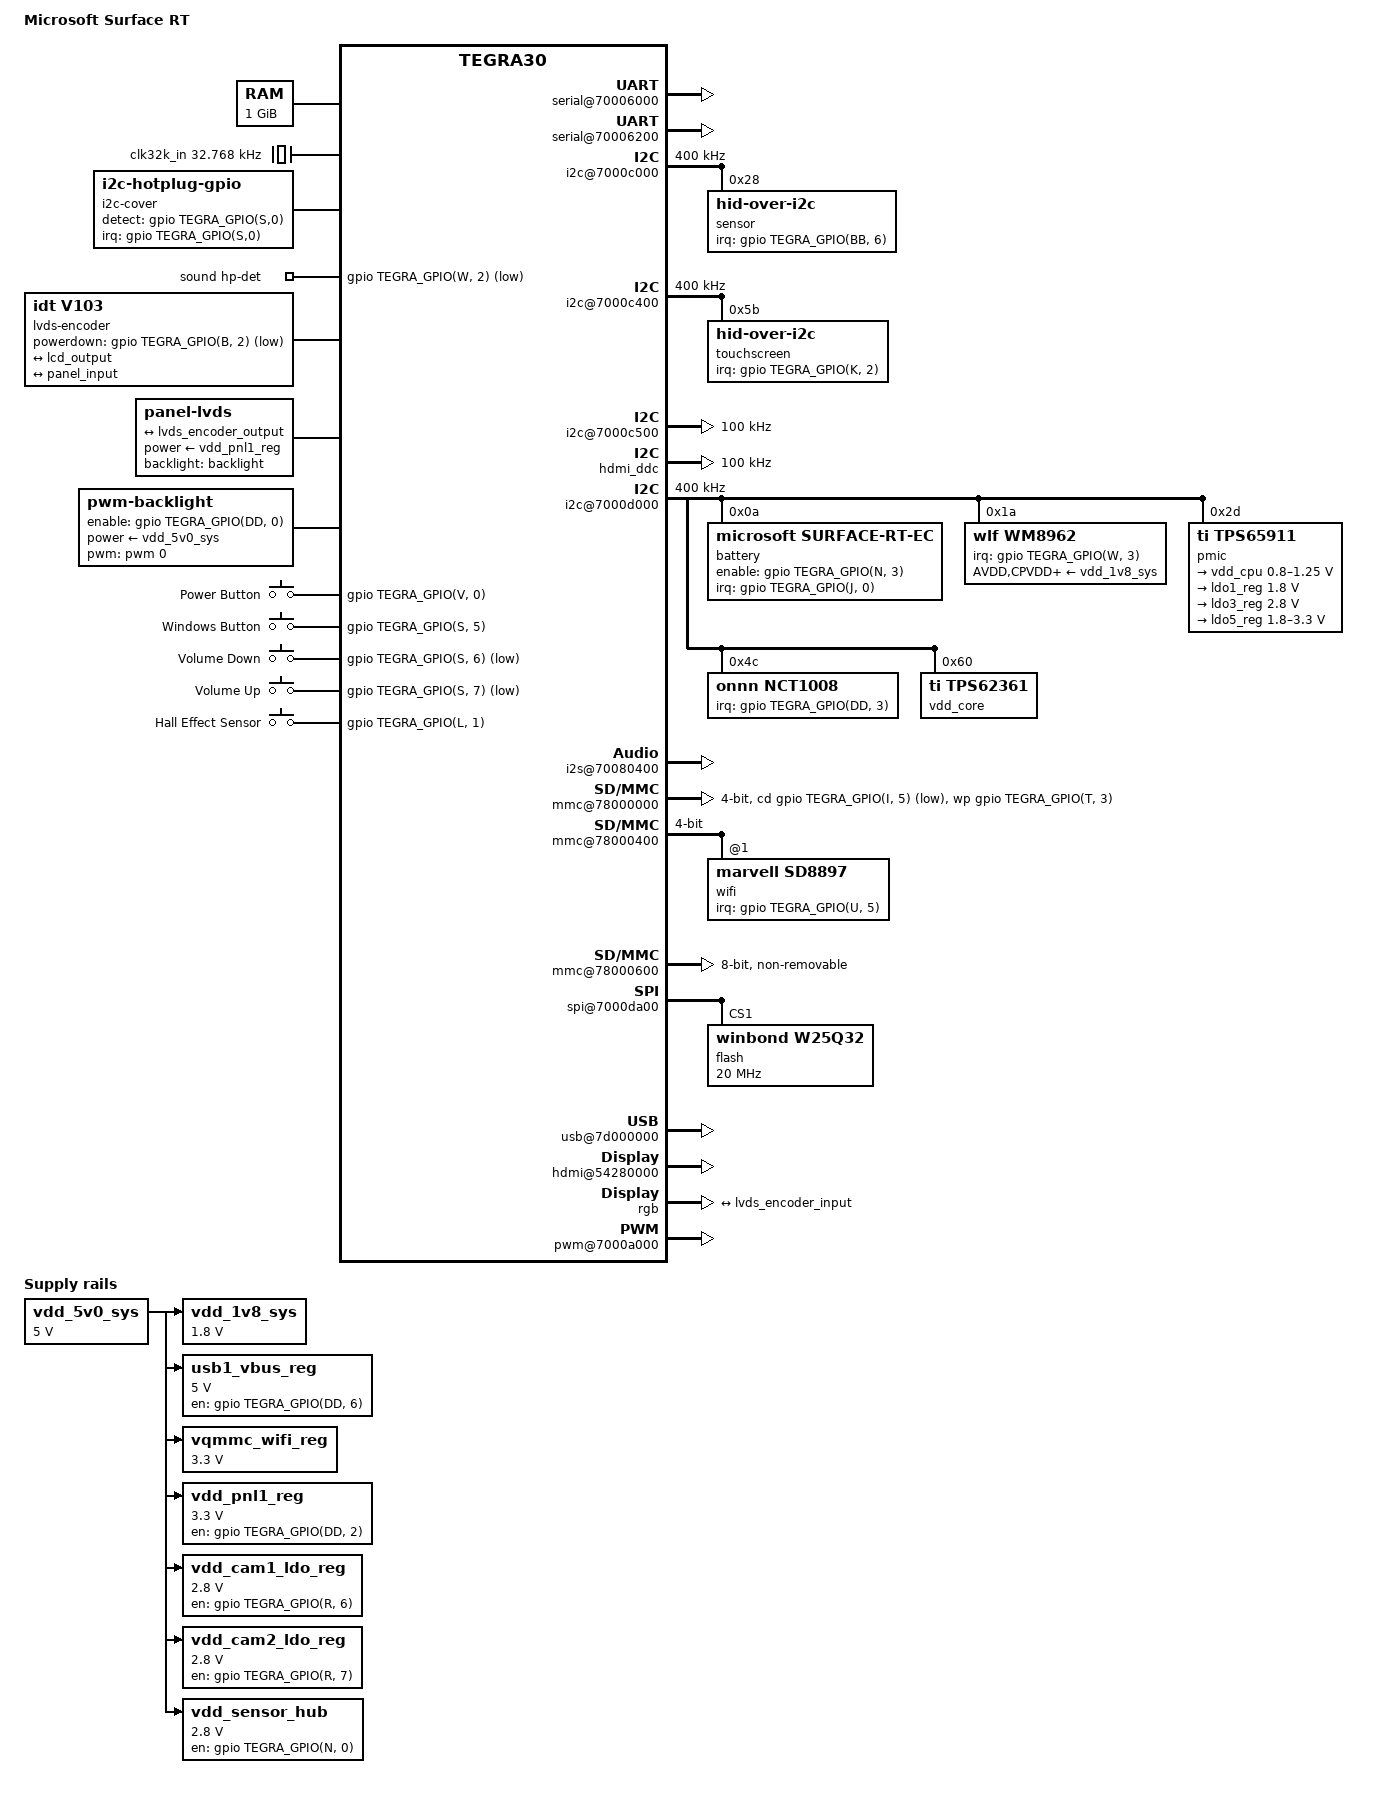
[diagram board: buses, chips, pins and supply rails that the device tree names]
// SPDX-License-Identifier: GPL-2.0

/dts-v1/;

#include "tegra30.dtsi"
#include "tegra30-cpu-opp.dtsi"
#include "tegra30-cpu-opp-microvolt.dtsi"
#include <dt-bindings/input/input.h>

/ {
	model = "Microsoft Surface RT";
	compatible = "microsoft,surface-rt", "nvidia,tegra30";

	aliases {
		mmc0 = &sdmmc4; /* eMMC */
		mmc1 = &sdmmc1; /* uSD slot */
		mmc2 = &sdmmc3; /* WiFi */
		rtc0 = &pmic;
		rtc1 = "/rtc@7000e000";
		serial0 = &uarta; /* console */
		serial1 = &uartc; /* Bluetooth */
	};

	chosen {
		stdout-path = "serial0:115200n8";
	};

	/* 2GB DDR3 Memory */
	memory@80000000 {
		reg = <0x80000000 0x40000000>; // 1 GiB is wrong size but 2GB doesn't work atm
	};

	/* clock from PMIC */
	clk32k_in: clock-32 {
		compatible = "fixed-clock";
		clock-frequency = <32768>;
		#clock-cells = <0>;
	};

	pinmux@70000868 {
		pinctrl-names = "default";
		pinctrl-0 = <&state_default>;

		state_default: pinmux {
			/* HDMI HOTPLUG_DETECT */
			hdmi-interrupt {
				nvidia,pins = "hdmi_int_pn7";
				nvidia,function = "hdmi";
				nvidia,pull = <TEGRA_PIN_PULL_NONE>;
				nvidia,tristate = <TEGRA_PIN_ENABLE>;
				nvidia,enable-input = <TEGRA_PIN_ENABLE>;
			};

			vol-keys {
				nvidia,pins = "kb_row14_ps6", //down
					      "kb_row15_ps7"; //up
				nvidia,pull = <TEGRA_PIN_PULL_NONE>;
				nvidia,tristate = <TEGRA_PIN_ENABLE>;
				nvidia,enable-input = <TEGRA_PIN_ENABLE>;
			};

			backlight-pwm {
				nvidia,pins = "gmi_ad8_ph0";
				nvidia,function = "pwm0";
				nvidia,pull = <TEGRA_PIN_PULL_NONE>;
				nvidia,tristate = <TEGRA_PIN_DISABLE>;
				nvidia,enable-input = <TEGRA_PIN_DISABLE>;
			};

			wifi-interrupt {
				nvidia,pins = "pu5";
				nvidia,pull = <TEGRA_PIN_PULL_DOWN>;
				nvidia,tristate = <TEGRA_PIN_DISABLE>;
				nvidia,enable-input = <TEGRA_PIN_ENABLE>;
			};

			sdmmc1-wp {
				nvidia,pins = "vi_d11_pt3";
				nvidia,pull = <TEGRA_PIN_PULL_NONE>;
				nvidia,tristate = <TEGRA_PIN_DISABLE>;
				nvidia,enable-input = <TEGRA_PIN_ENABLE>;
			};

			charger-interrupt {
				nvidia,pins = "gmi_cs0_n_pj0";
				nvidia,pull = <TEGRA_PIN_PULL_NONE>;
				nvidia,tristate = <TEGRA_PIN_ENABLE>;
				nvidia,enable-input = <TEGRA_PIN_ENABLE>;
			};
		};
	};

	serial@70006000 {
		status = "okay";
	};

	serial@70006200 {
		status = "okay";
		compatible = "nvidia,tegra30-hsuart";

		/* Bluetooth - Marvell 88W8797*/
	};

	/* MS HID - I2C1 */
	i2c@7000c000 {
		status = "okay";
		clock-frequency = <400000>;

		/* Sensor Collection at 0x28 */
		sensor@28 {
			compatible = "hid-over-i2c";
			reg = <0x28>;
			hid-descr-addr = <0x0001>;
			interrupt-parent = <&gpio>;
			interrupts = <TEGRA_GPIO(BB, 6) IRQ_TYPE_LEVEL_LOW>;
		};
		/* EDID at 0x50*/
	};

	i2c-cover {
		compatible = "i2c-hotplug-gpio";

		#address-cells = <1>;
		#size-cells = <0>;

		interrupts-extended = <&gpio TEGRA_GPIO(S,0) IRQ_TYPE_EDGE_BOTH>;
		detect-gpios = <&gpio TEGRA_GPIO(S,0) GPIO_ACTIVE_HIGH>;

		i2c-parent = <&i2c1>;

		cover@0 {
			compatible = "hid-over-i2c";
			reg = <0x00>;
			hid-descr-addr = <0x0041>;
			interrupt-parent = <&gpio>;
			interrupts = <TEGRA_GPIO(O, 5) IRQ_TYPE_LEVEL_LOW>;
		};
	};

	/* Daughter board - I2C2 */
	i2c@7000c400 {
		status = "okay";
		clock-frequency = <400000>;

		/* Atmel Maxtouch, HID over I2C */
		touchscreen@5b {
			compatible = "hid-over-i2c";
			reg = <0x5b>;
			hid-descr-addr = <0x0000>;
			interrupt-parent = <&gpio>;
			interrupts = <TEGRA_GPIO(K, 2) IRQ_TYPE_LEVEL_LOW>;
		};
	};

	/* Cams - I2C3 */
	i2c@7000c500 {
		status = "okay";
		clock-frequency = <100000>;
		/* Cams at 0x10 and 0x72 */
	};

	/* HDMI DisplayDataChannel - I2C4 */
	hdmi_ddc: i2c@7000c700 {
		status = "okay";
		clock-frequency = <100000>;
	};

	/* System bus - I2C5 */
	i2c@7000d000 {
		status = "okay";
		clock-frequency = <400000>;

		battery@a {
			compatible = "microsoft,surface-rt-ec";
			reg = <0x0a>;
			enable-gpios = <&gpio TEGRA_GPIO(N, 3) GPIO_ACTIVE_HIGH>;
			interrupt-parent = <&gpio>;
			interrupts = <TEGRA_GPIO(J, 0) IRQ_TYPE_EDGE_RISING>;
		};

		wm8962: audio-codec@1a {
			compatible = "wlf,wm8962";
			reg = <0x1a>;
			interrupt-parent = <&gpio>;
			interrupts = <TEGRA_GPIO(W, 3) IRQ_TYPE_LEVEL_HIGH>;

			AVDD-supply  = <&vdd_1v8_sys>;
			CPVDD-supply = <&vdd_1v8_sys>;
			DBVDD-supply = <&vdd_1v8_sys>;
			DCVDD-supply = <&vdd_1v8_sys>;
			MICVDD-supply = <&vdd_1v8_sys>;
			PLLVDD-supply = <&vdd_1v8_sys>;
			SPKVDD1-supply = <&vdd_1v8_sys>;
			SPKVDD2-supply = <&vdd_1v8_sys>;
		};

		pmic: pmic@2d {
			compatible = "ti,tps65911";
			reg = <0x2d>;

			interrupts = <GIC_SPI 86 IRQ_TYPE_LEVEL_HIGH>;
			#interrupt-cells = <2>;
			interrupt-controller;

			ti,system-power-controller;

			#gpio-cells = <2>;
			gpio-controller;

			regulators {
				vdd_cpu: vddctrl {
					regulator-name = "vdd_cpu,vdd_sys";
					regulator-min-microvolt = <800000>;
					regulator-max-microvolt = <1250000>;
					regulator-coupled-with = <&vdd_core>;
					regulator-coupled-max-spread = <300000>;
					regulator-max-step-microvolt = <100000>;
					regulator-always-on;
					ti,regulator-ext-sleep-control = <1>;

					nvidia,tegra-cpu-regulator;
				};

				ldo1_reg: ldo1 {
					regulator-name = "tCoverAndSensorCollection";
					regulator-min-microvolt = <1800000>;
					regulator-max-microvolt = <1800000>;
					regulator-always-on;
					regulator-boot-on;
				};

				ldo3_reg: ldo3 {
					regulator-name = "tCoverPower";
					regulator-min-microvolt = <2800000>;
					regulator-max-microvolt = <2800000>;
					regulator-always-on;
					regulator-boot-on;
				};

				ldo5_reg: ldo5 {
					regulator-name = "vddio_sdmmc";
					regulator-min-microvolt = <1800000>;
					regulator-max-microvolt = <3300000>;
					regulator-always-on;
				};
			};
		};

		nct1008: temperature-sensor@4c {
			compatible = "onnn,nct1008";
			reg = <0x4c>;
			interrupt-parent = <&gpio>;
			interrupts = <TEGRA_GPIO(DD, 3) IRQ_TYPE_EDGE_FALLING>;
			#thermal-sensor-cells = <1>;
		};

		vdd_core: core-regulator@60 {
			compatible = "ti,tps62361";
			reg = <0x60>;

			regulator-name = "tps62361-vout";
			regulator-min-microvolt = <500000>;
			regulator-max-microvolt = <1350000>;
			regulator-coupled-with = <&vdd_cpu>;
			regulator-coupled-max-spread = <300000>;
			regulator-max-step-microvolt = <100000>;
			regulator-boot-on;
			regulator-always-on;
			ti,enable-vout-discharge;
			ti,vsel0-state-high;
			ti,vsel1-state-high;

			nvidia,tegra-core-regulator;
		};
	};

	pmc@7000e400 {
		status = "okay";
		nvidia,invert-interrupt;
		nvidia,suspend-mode = <2>;
		nvidia,cpu-pwr-good-time = <2000>;
		nvidia,cpu-pwr-off-time = <200>;
		nvidia,core-pwr-good-time = <3845 3845>;
		nvidia,core-pwr-off-time = <0>;
		nvidia,core-power-req-active-high;
		nvidia,sys-clock-req-active-high;

		core-supply = <&vdd_core>;

		i2c-thermtrip {
			nvidia,i2c-controller-id = <4>;
			nvidia,bus-addr = <0x2d>;
			nvidia,reg-addr = <0x3f>;
			nvidia,reg-data = <0x80>;
		};
	};

	memory-controller@7000f000 {
		emc-timings-0 {
			nvidia,ram-code = <0>;
			timing-51000000 {
				clock-frequency = <51000000>;
				nvidia,emem-configuration = <
					0x00010003 /* MC_EMEM_ARB_CFG */
					0xc0000010 /* MC_EMEM_ARB_OUTSTANDING_REQ */
					0x00000001 /* MC_EMEM_ARB_TIMING_RCD */
					0x00000001 /* MC_EMEM_ARB_TIMING_RP */
					0x00000002 /* MC_EMEM_ARB_TIMING_RC */
					0x00000000 /* MC_EMEM_ARB_TIMING_RAS */
					0x00000001 /* MC_EMEM_ARB_TIMING_FAW */
					0x00000001 /* MC_EMEM_ARB_TIMING_RRD */
					0x00000003 /* MC_EMEM_ARB_TIMING_RAP2PRE */
					0x00000008 /* MC_EMEM_ARB_TIMING_WAP2PRE */
					0x00000002 /* MC_EMEM_ARB_TIMING_R2R */
					0x00000001 /* MC_EMEM_ARB_TIMING_W2W */
					0x00000002 /* MC_EMEM_ARB_TIMING_R2W */
					0x00000006 /* MC_EMEM_ARB_TIMING_W2R */
					0x06020102 /* MC_EMEM_ARB_DA_TURNS */
					0x000a0502 /* MC_EMEM_ARB_DA_COVERS */
					0x74630303 /* MC_EMEM_ARB_MISC0 */
					0x001f0000 /* MC_EMEM_ARB_RING1_THROTTLE */
				>;
			};
			timing-102000000 {
				clock-frequency = <102000000>;
				nvidia,emem-configuration = <
					0x00000003 /* MC_EMEM_ARB_CFG */
					0xc0000018 /* MC_EMEM_ARB_OUTSTANDING_REQ */
					0x00000001 /* MC_EMEM_ARB_TIMING_RCD */
					0x00000001 /* MC_EMEM_ARB_TIMING_RP */
					0x00000003 /* MC_EMEM_ARB_TIMING_RC */
					0x00000000 /* MC_EMEM_ARB_TIMING_RAS */
					0x00000001 /* MC_EMEM_ARB_TIMING_FAW */
					0x00000001 /* MC_EMEM_ARB_TIMING_RRD */
					0x00000003 /* MC_EMEM_ARB_TIMING_RAP2PRE */
					0x00000008 /* MC_EMEM_ARB_TIMING_WAP2PRE */
					0x00000002 /* MC_EMEM_ARB_TIMING_R2R */
					0x00000001 /* MC_EMEM_ARB_TIMING_W2W */
					0x00000002 /* MC_EMEM_ARB_TIMING_R2W */
					0x00000006 /* MC_EMEM_ARB_TIMING_W2R */
					0x06020102 /* MC_EMEM_ARB_DA_TURNS */
					0x000a0503 /* MC_EMEM_ARB_DA_COVERS */
					0x73c30504 /* MC_EMEM_ARB_MISC0 */
					0x001f0000 /* MC_EMEM_ARB_RING1_THROTTLE */
				>;
			};
			timing-204000000 {
				clock-frequency = <204000000>;
				nvidia,emem-configuration = <
					0x00000006 /* MC_EMEM_ARB_CFG */
					0xc0000025 /* MC_EMEM_ARB_OUTSTANDING_REQ */
					0x00000001 /* MC_EMEM_ARB_TIMING_RCD */
					0x00000001 /* MC_EMEM_ARB_TIMING_RP */
					0x00000005 /* MC_EMEM_ARB_TIMING_RC */
					0x00000002 /* MC_EMEM_ARB_TIMING_RAS */
					0x00000003 /* MC_EMEM_ARB_TIMING_FAW */
					0x00000001 /* MC_EMEM_ARB_TIMING_RRD */
					0x00000003 /* MC_EMEM_ARB_TIMING_RAP2PRE */
					0x00000008 /* MC_EMEM_ARB_TIMING_WAP2PRE */
					0x00000002 /* MC_EMEM_ARB_TIMING_R2R */
					0x00000001 /* MC_EMEM_ARB_TIMING_W2W */
					0x00000002 /* MC_EMEM_ARB_TIMING_R2W */
					0x00000006 /* MC_EMEM_ARB_TIMING_W2R */
					0x06020102 /* MC_EMEM_ARB_DA_TURNS */
					0x000a0505 /* MC_EMEM_ARB_DA_COVERS */
					0x73840a06 /* MC_EMEM_ARB_MISC0 */
					0x001f0000 /* MC_EMEM_ARB_RING1_THROTTLE */
				>;
			};
			timing-375000000 {
				clock-frequency = <375000000>;
				nvidia,emem-configuration = <
					0x0000000b /* MC_EMEM_ARB_CFG */
					0xc0000044 /* MC_EMEM_ARB_OUTSTANDING_REQ */
					0x00000001 /* MC_EMEM_ARB_TIMING_RCD */
					0x00000002 /* MC_EMEM_ARB_TIMING_RP */
					0x00000009 /* MC_EMEM_ARB_TIMING_RC */
					0x00000005 /* MC_EMEM_ARB_TIMING_RAS */
					0x00000005 /* MC_EMEM_ARB_TIMING_FAW */
					0x00000001 /* MC_EMEM_ARB_TIMING_RRD */
					0x00000002 /* MC_EMEM_ARB_TIMING_RAP2PRE */
					0x00000008 /* MC_EMEM_ARB_TIMING_WAP2PRE */
					0x00000002 /* MC_EMEM_ARB_TIMING_R2R */
					0x00000002 /* MC_EMEM_ARB_TIMING_W2W */
					0x00000003 /* MC_EMEM_ARB_TIMING_R2W */
					0x00000006 /* MC_EMEM_ARB_TIMING_W2R */
					0x06030202 /* MC_EMEM_ARB_DA_TURNS */
					0x000d0709 /* MC_EMEM_ARB_DA_COVERS */
					0x7086110a /* MC_EMEM_ARB_MISC0 */
					0x001f0000 /* MC_EMEM_ARB_RING1_THROTTLE */
				>;
			};
			timing-750000000 {
				clock-frequency = <750000000>;
				nvidia,emem-configuration = <
					0x00000016 /* MC_EMEM_ARB_CFG */
					0xc0000087 /* MC_EMEM_ARB_OUTSTANDING_REQ */
					0x00000004 /* MC_EMEM_ARB_TIMING_RCD */
					0x00000005 /* MC_EMEM_ARB_TIMING_RP */
					0x00000012 /* MC_EMEM_ARB_TIMING_RC */
					0x0000000c /* MC_EMEM_ARB_TIMING_RAS */
					0x0000000b /* MC_EMEM_ARB_TIMING_FAW */
					0x00000002 /* MC_EMEM_ARB_TIMING_RRD */
					0x00000003 /* MC_EMEM_ARB_TIMING_RAP2PRE */
					0x0000000c /* MC_EMEM_ARB_TIMING_WAP2PRE */
					0x00000002 /* MC_EMEM_ARB_TIMING_R2R */
					0x00000002 /* MC_EMEM_ARB_TIMING_W2W */
					0x00000004 /* MC_EMEM_ARB_TIMING_R2W */
					0x00000008 /* MC_EMEM_ARB_TIMING_W2R */
					0x08040202 /* MC_EMEM_ARB_DA_TURNS */
					0x00160d12 /* MC_EMEM_ARB_DA_COVERS */
					0x710c2213 /* MC_EMEM_ARB_MISC0 */
					0x001f0000 /* MC_EMEM_ARB_RING1_THROTTLE */
				>;
			};
		};
		emc-timings-1 {
			nvidia,ram-code = <1>;
			timing-51000000 {
				clock-frequency = <51000000>;
				nvidia,emem-configuration = <
					0x00010003 /* MC_EMEM_ARB_CFG */
					0xc0000010 /* MC_EMEM_ARB_OUTSTANDING_REQ */
					0x00000001 /* MC_EMEM_ARB_TIMING_RCD */
					0x00000001 /* MC_EMEM_ARB_TIMING_RP */
					0x00000002 /* MC_EMEM_ARB_TIMING_RC */
					0x00000000 /* MC_EMEM_ARB_TIMING_RAS */
					0x00000001 /* MC_EMEM_ARB_TIMING_FAW */
					0x00000001 /* MC_EMEM_ARB_TIMING_RRD */
					0x00000003 /* MC_EMEM_ARB_TIMING_RAP2PRE */
					0x00000008 /* MC_EMEM_ARB_TIMING_WAP2PRE */
					0x00000002 /* MC_EMEM_ARB_TIMING_R2R */
					0x00000001 /* MC_EMEM_ARB_TIMING_W2W */
					0x00000002 /* MC_EMEM_ARB_TIMING_R2W */
					0x00000006 /* MC_EMEM_ARB_TIMING_W2R */
					0x06020102 /* MC_EMEM_ARB_DA_TURNS */
					0x000a0502 /* MC_EMEM_ARB_DA_COVERS */
					0x74630303 /* MC_EMEM_ARB_MISC0 */
					0x001f0000 /* MC_EMEM_ARB_RING1_THROTTLE */
				>;
			};
			timing-102000000 {
				clock-frequency = <102000000>;
				nvidia,emem-configuration = <
					0x00000003 /* MC_EMEM_ARB_CFG */
					0xc0000018 /* MC_EMEM_ARB_OUTSTANDING_REQ */
					0x00000001 /* MC_EMEM_ARB_TIMING_RCD */
					0x00000001 /* MC_EMEM_ARB_TIMING_RP */
					0x00000003 /* MC_EMEM_ARB_TIMING_RC */
					0x00000000 /* MC_EMEM_ARB_TIMING_RAS */
					0x00000001 /* MC_EMEM_ARB_TIMING_FAW */
					0x00000001 /* MC_EMEM_ARB_TIMING_RRD */
					0x00000003 /* MC_EMEM_ARB_TIMING_RAP2PRE */
					0x00000008 /* MC_EMEM_ARB_TIMING_WAP2PRE */
					0x00000002 /* MC_EMEM_ARB_TIMING_R2R */
					0x00000001 /* MC_EMEM_ARB_TIMING_W2W */
					0x00000002 /* MC_EMEM_ARB_TIMING_R2W */
					0x00000006 /* MC_EMEM_ARB_TIMING_W2R */
					0x06020102 /* MC_EMEM_ARB_DA_TURNS */
					0x000a0503 /* MC_EMEM_ARB_DA_COVERS */
					0x73c30504 /* MC_EMEM_ARB_MISC0 */
					0x001f0000 /* MC_EMEM_ARB_RING1_THROTTLE */
				>;
			};
			timing-204000000 {
				clock-frequency = <204000000>;
				nvidia,emem-configuration = <
					0x00000006 /* MC_EMEM_ARB_CFG */
					0xc0000025 /* MC_EMEM_ARB_OUTSTANDING_REQ */
					0x00000001 /* MC_EMEM_ARB_TIMING_RCD */
					0x00000001 /* MC_EMEM_ARB_TIMING_RP */
					0x00000005 /* MC_EMEM_ARB_TIMING_RC */
					0x00000002 /* MC_EMEM_ARB_TIMING_RAS */
					0x00000003 /* MC_EMEM_ARB_TIMING_FAW */
					0x00000001 /* MC_EMEM_ARB_TIMING_RRD */
					0x00000003 /* MC_EMEM_ARB_TIMING_RAP2PRE */
					0x00000008 /* MC_EMEM_ARB_TIMING_WAP2PRE */
					0x00000002 /* MC_EMEM_ARB_TIMING_R2R */
					0x00000001 /* MC_EMEM_ARB_TIMING_W2W */
					0x00000002 /* MC_EMEM_ARB_TIMING_R2W */
					0x00000006 /* MC_EMEM_ARB_TIMING_W2R */
					0x06020102 /* MC_EMEM_ARB_DA_TURNS */
					0x000a0505 /* MC_EMEM_ARB_DA_COVERS */
					0x73840a06 /* MC_EMEM_ARB_MISC0 */
					0x001f0000 /* MC_EMEM_ARB_RING1_THROTTLE */
				>;
			};
			timing-375000000 {
				clock-frequency = <375000000>;
				nvidia,emem-configuration = <
					0x0000000b /* MC_EMEM_ARB_CFG */
					0xc0000044 /* MC_EMEM_ARB_OUTSTANDING_REQ */
					0x00000001 /* MC_EMEM_ARB_TIMING_RCD */
					0x00000002 /* MC_EMEM_ARB_TIMING_RP */
					0x00000009 /* MC_EMEM_ARB_TIMING_RC */
					0x00000005 /* MC_EMEM_ARB_TIMING_RAS */
					0x00000005 /* MC_EMEM_ARB_TIMING_FAW */
					0x00000001 /* MC_EMEM_ARB_TIMING_RRD */
					0x00000002 /* MC_EMEM_ARB_TIMING_RAP2PRE */
					0x00000008 /* MC_EMEM_ARB_TIMING_WAP2PRE */
					0x00000002 /* MC_EMEM_ARB_TIMING_R2R */
					0x00000002 /* MC_EMEM_ARB_TIMING_W2W */
					0x00000003 /* MC_EMEM_ARB_TIMING_R2W */
					0x00000006 /* MC_EMEM_ARB_TIMING_W2R */
					0x06030202 /* MC_EMEM_ARB_DA_TURNS */
					0x000d0709 /* MC_EMEM_ARB_DA_COVERS */
					0x7086110a /* MC_EMEM_ARB_MISC0 */
					0x001f0000 /* MC_EMEM_ARB_RING1_THROTTLE */
				>;
			};
			timing-750000000 {
				clock-frequency = <750000000>;
				nvidia,emem-configuration = <
					0x00000016 /* MC_EMEM_ARB_CFG */
					0xc0000087 /* MC_EMEM_ARB_OUTSTANDING_REQ */
					0x00000004 /* MC_EMEM_ARB_TIMING_RCD */
					0x00000005 /* MC_EMEM_ARB_TIMING_RP */
					0x00000012 /* MC_EMEM_ARB_TIMING_RC */
					0x0000000c /* MC_EMEM_ARB_TIMING_RAS */
					0x0000000b /* MC_EMEM_ARB_TIMING_FAW */
					0x00000002 /* MC_EMEM_ARB_TIMING_RRD */
					0x00000003 /* MC_EMEM_ARB_TIMING_RAP2PRE */
					0x0000000c /* MC_EMEM_ARB_TIMING_WAP2PRE */
					0x00000002 /* MC_EMEM_ARB_TIMING_R2R */
					0x00000002 /* MC_EMEM_ARB_TIMING_W2W */
					0x00000004 /* MC_EMEM_ARB_TIMING_R2W */
					0x00000008 /* MC_EMEM_ARB_TIMING_W2R */
					0x08040202 /* MC_EMEM_ARB_DA_TURNS */
					0x00160d12 /* MC_EMEM_ARB_DA_COVERS */
					0x710c2213 /* MC_EMEM_ARB_MISC0 */
					0x001f0000 /* MC_EMEM_ARB_RING1_THROTTLE */
				>;
			};
		};
		emc-timings-2 {
			nvidia,ram-code = <2>;
			timing-51000000 {
				clock-frequency = <51000000>;
				nvidia,emem-configuration = <
					0x00010001 /* MC_EMEM_ARB_CFG */
					0xc0000010 /* MC_EMEM_ARB_OUTSTANDING_REQ */
					0x00000001 /* MC_EMEM_ARB_TIMING_RCD */
					0x00000001 /* MC_EMEM_ARB_TIMING_RP */
					0x00000002 /* MC_EMEM_ARB_TIMING_RC */
					0x00000000 /* MC_EMEM_ARB_TIMING_RAS */
					0x00000001 /* MC_EMEM_ARB_TIMING_FAW */
					0x00000001 /* MC_EMEM_ARB_TIMING_RRD */
					0x00000002 /* MC_EMEM_ARB_TIMING_RAP2PRE */
					0x00000008 /* MC_EMEM_ARB_TIMING_WAP2PRE */
					0x00000002 /* MC_EMEM_ARB_TIMING_R2R */
					0x00000001 /* MC_EMEM_ARB_TIMING_W2W */
					0x00000002 /* MC_EMEM_ARB_TIMING_R2W */
					0x00000006 /* MC_EMEM_ARB_TIMING_W2R */
					0x06020102 /* MC_EMEM_ARB_DA_TURNS */
					0x000a0402 /* MC_EMEM_ARB_DA_COVERS */
					0x74e30303 /* MC_EMEM_ARB_MISC0 */
					0x001f0000 /* MC_EMEM_ARB_RING1_THROTTLE */
				>;
			};
			timing-102000000 {
				clock-frequency = <102000000>;
				nvidia,emem-configuration = <
					0x00000001 /* MC_EMEM_ARB_CFG */
					0xc0000018 /* MC_EMEM_ARB_OUTSTANDING_REQ */
					0x00000001 /* MC_EMEM_ARB_TIMING_RCD */
					0x00000001 /* MC_EMEM_ARB_TIMING_RP */
					0x00000003 /* MC_EMEM_ARB_TIMING_RC */
					0x00000000 /* MC_EMEM_ARB_TIMING_RAS */
					0x00000001 /* MC_EMEM_ARB_TIMING_FAW */
					0x00000001 /* MC_EMEM_ARB_TIMING_RRD */
					0x00000002 /* MC_EMEM_ARB_TIMING_RAP2PRE */
					0x00000008 /* MC_EMEM_ARB_TIMING_WAP2PRE */
					0x00000002 /* MC_EMEM_ARB_TIMING_R2R */
					0x00000001 /* MC_EMEM_ARB_TIMING_W2W */
					0x00000002 /* MC_EMEM_ARB_TIMING_R2W */
					0x00000006 /* MC_EMEM_ARB_TIMING_W2R */
					0x06020102 /* MC_EMEM_ARB_DA_TURNS */
					0x000a0403 /* MC_EMEM_ARB_DA_COVERS */
					0x74430504 /* MC_EMEM_ARB_MISC0 */
					0x001f0000 /* MC_EMEM_ARB_RING1_THROTTLE */
				>;
			};
			timing-375000000 {
				clock-frequency = <375000000>;
				nvidia,emem-configuration = <
					0x00000005 /* MC_EMEM_ARB_CFG */
					0xc0000044 /* MC_EMEM_ARB_OUTSTANDING_REQ */
					0x00000001 /* MC_EMEM_ARB_TIMING_RCD */
					0x00000002 /* MC_EMEM_ARB_TIMING_RP */
					0x00000009 /* MC_EMEM_ARB_TIMING_RC */
					0x00000005 /* MC_EMEM_ARB_TIMING_RAS */
					0x00000005 /* MC_EMEM_ARB_TIMING_FAW */
					0x00000001 /* MC_EMEM_ARB_TIMING_RRD */
					0x00000002 /* MC_EMEM_ARB_TIMING_RAP2PRE */
					0x00000008 /* MC_EMEM_ARB_TIMING_WAP2PRE */
					0x00000002 /* MC_EMEM_ARB_TIMING_R2R */
					0x00000002 /* MC_EMEM_ARB_TIMING_W2W */
					0x00000003 /* MC_EMEM_ARB_TIMING_R2W */
					0x00000006 /* MC_EMEM_ARB_TIMING_W2R */
					0x06030202 /* MC_EMEM_ARB_DA_TURNS */
					0x000d0709 /* MC_EMEM_ARB_DA_COVERS */
					0x7086110a /* MC_EMEM_ARB_MISC0 */
					0x001f0000 /* MC_EMEM_ARB_RING1_THROTTLE */
				>;
			};
			timing-750000000 {
				clock-frequency = <750000000>;
				nvidia,emem-configuration = <
					0x0000000b /* MC_EMEM_ARB_CFG */
					0xc0000087 /* MC_EMEM_ARB_OUTSTANDING_REQ */
					0x00000004 /* MC_EMEM_ARB_TIMING_RCD */
					0x00000005 /* MC_EMEM_ARB_TIMING_RP */
					0x00000012 /* MC_EMEM_ARB_TIMING_RC */
					0x0000000c /* MC_EMEM_ARB_TIMING_RAS */
					0x0000000b /* MC_EMEM_ARB_TIMING_FAW */
					0x00000003 /* MC_EMEM_ARB_TIMING_RRD */
					0x00000003 /* MC_EMEM_ARB_TIMING_RAP2PRE */
					0x0000000c /* MC_EMEM_ARB_TIMING_WAP2PRE */
					0x00000002 /* MC_EMEM_ARB_TIMING_R2R */
					0x00000002 /* MC_EMEM_ARB_TIMING_W2W */
					0x00000004 /* MC_EMEM_ARB_TIMING_R2W */
					0x00000008 /* MC_EMEM_ARB_TIMING_W2R */
					0x08040202 /* MC_EMEM_ARB_DA_TURNS */
					0x00160d12 /* MC_EMEM_ARB_DA_COVERS */
					0x704c2213 /* MC_EMEM_ARB_MISC0 */
					0x001f0000 /* MC_EMEM_ARB_RING1_THROTTLE */
				>;
			};
		};
		emc-timings-3 {
			nvidia,ram-code = <3>;
			timing-51000000 {
				clock-frequency = <51000000>;
				nvidia,emem-configuration = <
					0x00010003 /* MC_EMEM_ARB_CFG */
					0xc0000010 /* MC_EMEM_ARB_OUTSTANDING_REQ */
					0x00000001 /* MC_EMEM_ARB_TIMING_RCD */
					0x00000001 /* MC_EMEM_ARB_TIMING_RP */
					0x00000002 /* MC_EMEM_ARB_TIMING_RC */
					0x00000000 /* MC_EMEM_ARB_TIMING_RAS */
					0x00000001 /* MC_EMEM_ARB_TIMING_FAW */
					0x00000001 /* MC_EMEM_ARB_TIMING_RRD */
					0x00000003 /* MC_EMEM_ARB_TIMING_RAP2PRE */
					0x00000008 /* MC_EMEM_ARB_TIMING_WAP2PRE */
					0x00000002 /* MC_EMEM_ARB_TIMING_R2R */
					0x00000001 /* MC_EMEM_ARB_TIMING_W2W */
					0x00000002 /* MC_EMEM_ARB_TIMING_R2W */
					0x00000006 /* MC_EMEM_ARB_TIMING_W2R */
					0x06020102 /* MC_EMEM_ARB_DA_TURNS */
					0x000a0502 /* MC_EMEM_ARB_DA_COVERS */
					0x74e30303 /* MC_EMEM_ARB_MISC0 */
					0x001f0000 /* MC_EMEM_ARB_RING1_THROTTLE */
				>;
			};
			timing-102000000 {
				clock-frequency = <102000000>;
				nvidia,emem-configuration = <
					0x00000003 /* MC_EMEM_ARB_CFG */
					0xc0000018 /* MC_EMEM_ARB_OUTSTANDING_REQ */
					0x00000001 /* MC_EMEM_ARB_TIMING_RCD */
					0x00000001 /* MC_EMEM_ARB_TIMING_RP */
					0x00000003 /* MC_EMEM_ARB_TIMING_RC */
					0x00000000 /* MC_EMEM_ARB_TIMING_RAS */
					0x00000001 /* MC_EMEM_ARB_TIMING_FAW */
					0x00000001 /* MC_EMEM_ARB_TIMING_RRD */
					0x00000003 /* MC_EMEM_ARB_TIMING_RAP2PRE */
					0x00000008 /* MC_EMEM_ARB_TIMING_WAP2PRE */
					0x00000002 /* MC_EMEM_ARB_TIMING_R2R */
					0x00000001 /* MC_EMEM_ARB_TIMING_W2W */
					0x00000002 /* MC_EMEM_ARB_TIMING_R2W */
					0x00000006 /* MC_EMEM_ARB_TIMING_W2R */
					0x06020102 /* MC_EMEM_ARB_DA_TURNS */
					0x000a0503 /* MC_EMEM_ARB_DA_COVERS */
					0x74430504 /* MC_EMEM_ARB_MISC0 */
					0x001f0000 /* MC_EMEM_ARB_RING1_THROTTLE */
				>;
			};
			timing-204000000 {
				clock-frequency = <204000000>;
				nvidia,emem-configuration = <
					0x00000006 /* MC_EMEM_ARB_CFG */
					0xc0000025 /* MC_EMEM_ARB_OUTSTANDING_REQ */
					0x00000001 /* MC_EMEM_ARB_TIMING_RCD */
					0x00000001 /* MC_EMEM_ARB_TIMING_RP */
					0x00000005 /* MC_EMEM_ARB_TIMING_RC */
					0x00000002 /* MC_EMEM_ARB_TIMING_RAS */
					0x00000003 /* MC_EMEM_ARB_TIMING_FAW */
					0x00000001 /* MC_EMEM_ARB_TIMING_RRD */
					0x00000003 /* MC_EMEM_ARB_TIMING_RAP2PRE */
					0x00000008 /* MC_EMEM_ARB_TIMING_WAP2PRE */
					0x00000002 /* MC_EMEM_ARB_TIMING_R2R */
					0x00000001 /* MC_EMEM_ARB_TIMING_W2W */
					0x00000002 /* MC_EMEM_ARB_TIMING_R2W */
					0x00000006 /* MC_EMEM_ARB_TIMING_W2R */
					0x06020102 /* MC_EMEM_ARB_DA_TURNS */
					0x000a0505 /* MC_EMEM_ARB_DA_COVERS */
					0x74040a06 /* MC_EMEM_ARB_MISC0 */
					0x001f0000 /* MC_EMEM_ARB_RING1_THROTTLE */
				>;
			};
			timing-375000000 {
				clock-frequency = <375000000>;
				nvidia,emem-configuration = <
					0x0000000b /* MC_EMEM_ARB_CFG */
					0xc0000044 /* MC_EMEM_ARB_OUTSTANDING_REQ */
					0x00000001 /* MC_EMEM_ARB_TIMING_RCD */
					0x00000002 /* MC_EMEM_ARB_TIMING_RP */
					0x00000009 /* MC_EMEM_ARB_TIMING_RC */
					0x00000005 /* MC_EMEM_ARB_TIMING_RAS */
					0x00000005 /* MC_EMEM_ARB_TIMING_FAW */
					0x00000001 /* MC_EMEM_ARB_TIMING_RRD */
					0x00000002 /* MC_EMEM_ARB_TIMING_RAP2PRE */
					0x00000008 /* MC_EMEM_ARB_TIMING_WAP2PRE */
					0x00000002 /* MC_EMEM_ARB_TIMING_R2R */
					0x00000002 /* MC_EMEM_ARB_TIMING_W2W */
					0x00000003 /* MC_EMEM_ARB_TIMING_R2W */
					0x00000006 /* MC_EMEM_ARB_TIMING_W2R */
					0x06030202 /* MC_EMEM_ARB_DA_TURNS */
					0x000d0709 /* MC_EMEM_ARB_DA_COVERS */
					0x7086110a /* MC_EMEM_ARB_MISC0 */
					0x001f0000 /* MC_EMEM_ARB_RING1_THROTTLE */
				>;
			};
			timing-750000000 {
				clock-frequency = <750000000>;
				nvidia,emem-configuration = <
					0x00000016 /* MC_EMEM_ARB_CFG */
					0xc0000087 /* MC_EMEM_ARB_OUTSTANDING_REQ */
					0x00000004 /* MC_EMEM_ARB_TIMING_RCD */
					0x00000005 /* MC_EMEM_ARB_TIMING_RP */
					0x00000012 /* MC_EMEM_ARB_TIMING_RC */
					0x0000000c /* MC_EMEM_ARB_TIMING_RAS */
					0x0000000b /* MC_EMEM_ARB_TIMING_FAW */
					0x00000003 /* MC_EMEM_ARB_TIMING_RRD */
					0x00000003 /* MC_EMEM_ARB_TIMING_RAP2PRE */
					0x0000000c /* MC_EMEM_ARB_TIMING_WAP2PRE */
					0x00000002 /* MC_EMEM_ARB_TIMING_R2R */
					0x00000002 /* MC_EMEM_ARB_TIMING_W2W */
					0x00000004 /* MC_EMEM_ARB_TIMING_R2W */
					0x00000008 /* MC_EMEM_ARB_TIMING_W2R */
					0x08040202 /* MC_EMEM_ARB_DA_TURNS */
					0x00160d12 /* MC_EMEM_ARB_DA_COVERS */
					0x710c2213 /* MC_EMEM_ARB_MISC0 */
					0x001f0000 /* MC_EMEM_ARB_RING1_THROTTLE */
				>;
			};
		};
	};

	memory-controller@7000f400 {
		emc-timings-0 {
			nvidia,ram-code = <0>;
			timing-51000000 {
				clock-frequency = <51000000>;
				nvidia,emc-auto-cal-interval = <0x001fffff>;
				nvidia,emc-mode-1 = <0x80100003>;
				nvidia,emc-mode-2 = <0x80200008>;
				nvidia,emc-mode-reset = <0x80001221>;
				nvidia,emc-zcal-cnt-long = <0x00000040>;
				nvidia,emc-cfg-periodic-qrst;
				nvidia,emc-cfg-dyn-self-ref;
				nvidia,emc-configuration = <
					0x00000002 /* EMC_RC */
					0x0000000d /* EMC_RFC */
					0x00000001 /* EMC_RAS */
					0x00000000 /* EMC_RP */
					0x00000002 /* EMC_R2W */
					0x0000000a /* EMC_W2R */
					0x00000005 /* EMC_R2P */
					0x0000000b /* EMC_W2P */
					0x00000000 /* EMC_RD_RCD */
					0x00000000 /* EMC_WR_RCD */
					0x00000003 /* EMC_RRD */
					0x00000001 /* EMC_REXT */
					0x00000000 /* EMC_WEXT */
					0x00000005 /* EMC_WDV */
					0x00000005 /* EMC_QUSE */
					0x00000004 /* EMC_QRST */
					0x0000000a /* EMC_QSAFE */
					0x0000000b /* EMC_RDV */
					0x00000181 /* EMC_REFRESH */
					0x00000000 /* EMC_BURST_REFRESH_NUM */
					0x00000060 /* EMC_PRE_REFRESH_REQ_CNT */
					0x00000002 /* EMC_PDEX2WR */
					0x00000002 /* EMC_PDEX2RD */
					0x00000001 /* EMC_PCHG2PDEN */
					0x00000000 /* EMC_ACT2PDEN */
					0x00000007 /* EMC_AR2PDEN */
					0x0000000f /* EMC_RW2PDEN */
					0x0000000e /* EMC_TXSR */
					0x0000000e /* EMC_TXSRDLL */
					0x00000004 /* EMC_TCKE */
					0x00000002 /* EMC_TFAW */
					0x00000000 /* EMC_TRPAB */
					0x00000004 /* EMC_TCLKSTABLE */
					0x00000005 /* EMC_TCLKSTOP */
					0x0000018e /* EMC_TREFBW */
					0x00000006 /* EMC_QUSE_EXTRA */
					0x00000004 /* EMC_FBIO_CFG6 */
					0x00000000 /* EMC_ODT_WRITE */
					0x00000000 /* EMC_ODT_READ */
					0x00004288 /* EMC_FBIO_CFG5 */
					0x007800a4 /* EMC_CFG_DIG_DLL */
					0x00008000 /* EMC_CFG_DIG_DLL_PERIOD */
					0x000fc000 /* EMC_DLL_XFORM_DQS0 */
					0x000fc000 /* EMC_DLL_XFORM_DQS1 */
					0x000fc000 /* EMC_DLL_XFORM_DQS2 */
					0x000fc000 /* EMC_DLL_XFORM_DQS3 */
					0x000fc000 /* EMC_DLL_XFORM_DQS4 */
					0x000fc000 /* EMC_DLL_XFORM_DQS5 */
					0x000fc000 /* EMC_DLL_XFORM_DQS6 */
					0x000fc000 /* EMC_DLL_XFORM_DQS7 */
					0x00000000 /* EMC_DLL_XFORM_QUSE0 */
					0x00000000 /* EMC_DLL_XFORM_QUSE1 */
					0x00000000 /* EMC_DLL_XFORM_QUSE2 */
					0x00000000 /* EMC_DLL_XFORM_QUSE3 */
					0x00000000 /* EMC_DLL_XFORM_QUSE4 */
					0x00000000 /* EMC_DLL_XFORM_QUSE5 */
					0x00000000 /* EMC_DLL_XFORM_QUSE6 */
					0x00000000 /* EMC_DLL_XFORM_QUSE7 */
					0x00000000 /* EMC_DLI_TRIM_TXDQS0 */
					0x00000000 /* EMC_DLI_TRIM_TXDQS1 */
					0x00000000 /* EMC_DLI_TRIM_TXDQS2 */
					0x00000000 /* EMC_DLI_TRIM_TXDQS3 */
					0x00000000 /* EMC_DLI_TRIM_TXDQS4 */
					0x00000000 /* EMC_DLI_TRIM_TXDQS5 */
					0x00000000 /* EMC_DLI_TRIM_TXDQS6 */
					0x00000000 /* EMC_DLI_TRIM_TXDQS7 */
					0x000fc000 /* EMC_DLL_XFORM_DQ0 */
					0x000fc000 /* EMC_DLL_XFORM_DQ1 */
					0x000fc000 /* EMC_DLL_XFORM_DQ2 */
					0x000fc000 /* EMC_DLL_XFORM_DQ3 */
					0x000002a0 /* EMC_XM2CMDPADCTRL */
					0x0800211c /* EMC_XM2DQSPADCTRL2 */
					0x00000000 /* EMC_XM2DQPADCTRL2 */
					0x77fff884 /* EMC_XM2CLKPADCTRL */
					0x01f1f108 /* EMC_XM2COMPPADCTRL */
					0x05057404 /* EMC_XM2VTTGENPADCTRL */
					0x54000007 /* EMC_XM2VTTGENPADCTRL2 */
					0x08000168 /* EMC_XM2QUSEPADCTRL */
					0x08000000 /* EMC_XM2DQSPADCTRL3 */
					0x00000802 /* EMC_CTT_TERM_CTRL */
					0x00000000 /* EMC_ZCAL_INTERVAL */
					0x00000040 /* EMC_ZCAL_WAIT_CNT */
					0x000c000c /* EMC_MRS_WAIT_CNT */
					0xa0f10000 /* EMC_AUTO_CAL_CONFIG */
					0x00000000 /* EMC_CTT */
					0x00000000 /* EMC_CTT_DURATION */
					0x8000040b /* EMC_DYN_SELF_REF_CONTROL */
					0xe8000000 /* EMC_FBIO_SPARE */
					0xff00ff00 /* EMC_CFG_RSV */
				>;
			};
			timing-102000000 {
				clock-frequency = <102000000>;
				nvidia,emc-auto-cal-interval = <0x001fffff>;
				nvidia,emc-mode-1 = <0x80100003>;
				nvidia,emc-mode-2 = <0x80200008>;
				nvidia,emc-mode-reset = <0x80001221>;
				nvidia,emc-zcal-cnt-long = <0x00000040>;
				nvidia,emc-cfg-periodic-qrst;
				nvidia,emc-cfg-dyn-self-ref;
				nvidia,emc-configuration = <
					0x00000004 /* EMC_RC */
					0x0000001a /* EMC_RFC */
					0x00000003 /* EMC_RAS */
					0x00000001 /* EMC_RP */
					0x00000002 /* EMC_R2W */
					0x0000000a /* EMC_W2R */
					0x00000005 /* EMC_R2P */
					0x0000000b /* EMC_W2P */
					0x00000001 /* EMC_RD_RCD */
					0x00000001 /* EMC_WR_RCD */
					0x00000003 /* EMC_RRD */
					0x00000001 /* EMC_REXT */
					0x00000000 /* EMC_WEXT */
					0x00000005 /* EMC_WDV */
					0x00000005 /* EMC_QUSE */
					0x00000004 /* EMC_QRST */
					0x0000000a /* EMC_QSAFE */
					0x0000000b /* EMC_RDV */
					0x00000303 /* EMC_REFRESH */
					0x00000000 /* EMC_BURST_REFRESH_NUM */
					0x000000c0 /* EMC_PRE_REFRESH_REQ_CNT */
					0x00000002 /* EMC_PDEX2WR */
					0x00000002 /* EMC_PDEX2RD */
					0x00000001 /* EMC_PCHG2PDEN */
					0x00000000 /* EMC_ACT2PDEN */
					0x00000007 /* EMC_AR2PDEN */
					0x0000000f /* EMC_RW2PDEN */
					0x0000001c /* EMC_TXSR */
					0x0000001c /* EMC_TXSRDLL */
					0x00000004 /* EMC_TCKE */
					0x00000004 /* EMC_TFAW */
					0x00000000 /* EMC_TRPAB */
					0x00000004 /* EMC_TCLKSTABLE */
					0x00000005 /* EMC_TCLKSTOP */
					0x0000031c /* EMC_TREFBW */
					0x00000006 /* EMC_QUSE_EXTRA */
					0x00000004 /* EMC_FBIO_CFG6 */
					0x00000000 /* EMC_ODT_WRITE */
					0x00000000 /* EMC_ODT_READ */
					0x00004288 /* EMC_FBIO_CFG5 */
					0x007800a4 /* EMC_CFG_DIG_DLL */
					0x00008000 /* EMC_CFG_DIG_DLL_PERIOD */
					0x000fc000 /* EMC_DLL_XFORM_DQS0 */
					0x000fc000 /* EMC_DLL_XFORM_DQS1 */
					0x000fc000 /* EMC_DLL_XFORM_DQS2 */
					0x000fc000 /* EMC_DLL_XFORM_DQS3 */
					0x000fc000 /* EMC_DLL_XFORM_DQS4 */
					0x000fc000 /* EMC_DLL_XFORM_DQS5 */
					0x000fc000 /* EMC_DLL_XFORM_DQS6 */
					0x000fc000 /* EMC_DLL_XFORM_DQS7 */
					0x00000000 /* EMC_DLL_XFORM_QUSE0 */
					0x00000000 /* EMC_DLL_XFORM_QUSE1 */
					0x00000000 /* EMC_DLL_XFORM_QUSE2 */
					0x00000000 /* EMC_DLL_XFORM_QUSE3 */
					0x00000000 /* EMC_DLL_XFORM_QUSE4 */
					0x00000000 /* EMC_DLL_XFORM_QUSE5 */
					0x00000000 /* EMC_DLL_XFORM_QUSE6 */
					0x00000000 /* EMC_DLL_XFORM_QUSE7 */
					0x00000000 /* EMC_DLI_TRIM_TXDQS0 */
					0x00000000 /* EMC_DLI_TRIM_TXDQS1 */
					0x00000000 /* EMC_DLI_TRIM_TXDQS2 */
					0x00000000 /* EMC_DLI_TRIM_TXDQS3 */
					0x00000000 /* EMC_DLI_TRIM_TXDQS4 */
					0x00000000 /* EMC_DLI_TRIM_TXDQS5 */
					0x00000000 /* EMC_DLI_TRIM_TXDQS6 */
					0x00000000 /* EMC_DLI_TRIM_TXDQS7 */
					0x000fc000 /* EMC_DLL_XFORM_DQ0 */
					0x000fc000 /* EMC_DLL_XFORM_DQ1 */
					0x000fc000 /* EMC_DLL_XFORM_DQ2 */
					0x000fc000 /* EMC_DLL_XFORM_DQ3 */
					0x000002a0 /* EMC_XM2CMDPADCTRL */
					0x0800211c /* EMC_XM2DQSPADCTRL2 */
					0x00000000 /* EMC_XM2DQPADCTRL2 */
					0x77fff884 /* EMC_XM2CLKPADCTRL */
					0x01f1f108 /* EMC_XM2COMPPADCTRL */
					0x05057404 /* EMC_XM2VTTGENPADCTRL */
					0x54000007 /* EMC_XM2VTTGENPADCTRL2 */
					0x08000168 /* EMC_XM2QUSEPADCTRL */
					0x08000000 /* EMC_XM2DQSPADCTRL3 */
					0x00000802 /* EMC_CTT_TERM_CTRL */
					0x00000000 /* EMC_ZCAL_INTERVAL */
					0x00000040 /* EMC_ZCAL_WAIT_CNT */
					0x000c000c /* EMC_MRS_WAIT_CNT */
					0xa0f10000 /* EMC_AUTO_CAL_CONFIG */
					0x00000000 /* EMC_CTT */
					0x00000000 /* EMC_CTT_DURATION */
					0x80000713 /* EMC_DYN_SELF_REF_CONTROL */
					0xe8000000 /* EMC_FBIO_SPARE */
					0xff00ff00 /* EMC_CFG_RSV */
				>;
			};
			timing-204000000 {
				clock-frequency = <204000000>;
				nvidia,emc-auto-cal-interval = <0x001fffff>;
				nvidia,emc-mode-1 = <0x80100003>;
				nvidia,emc-mode-2 = <0x80200008>;
				nvidia,emc-mode-reset = <0x80001221>;
				nvidia,emc-zcal-cnt-long = <0x00000040>;
				nvidia,emc-cfg-periodic-qrst;
				nvidia,emc-cfg-dyn-self-ref;
				nvidia,emc-configuration = <
					0x00000009 /* EMC_RC */
					0x00000035 /* EMC_RFC */
					0x00000007 /* EMC_RAS */
					0x00000002 /* EMC_RP */
					0x00000002 /* EMC_R2W */
					0x0000000a /* EMC_W2R */
					0x00000005 /* EMC_R2P */
					0x0000000b /* EMC_W2P */
					0x00000002 /* EMC_RD_RCD */
					0x00000002 /* EMC_WR_RCD */
					0x00000003 /* EMC_RRD */
					0x00000001 /* EMC_REXT */
					0x00000000 /* EMC_WEXT */
					0x00000005 /* EMC_WDV */
					0x00000005 /* EMC_QUSE */
					0x00000004 /* EMC_QRST */
					0x0000000a /* EMC_QSAFE */
					0x0000000b /* EMC_RDV */
					0x00000607 /* EMC_REFRESH */
					0x00000000 /* EMC_BURST_REFRESH_NUM */
					0x00000181 /* EMC_PRE_REFRESH_REQ_CNT */
					0x00000002 /* EMC_PDEX2WR */
					0x00000002 /* EMC_PDEX2RD */
					0x00000001 /* EMC_PCHG2PDEN */
					0x00000000 /* EMC_ACT2PDEN */
					0x00000007 /* EMC_AR2PDEN */
					0x0000000f /* EMC_RW2PDEN */
					0x00000038 /* EMC_TXSR */
					0x00000038 /* EMC_TXSRDLL */
					0x00000004 /* EMC_TCKE */
					0x00000007 /* EMC_TFAW */
					0x00000000 /* EMC_TRPAB */
					0x00000004 /* EMC_TCLKSTABLE */
					0x00000005 /* EMC_TCLKSTOP */
					0x00000638 /* EMC_TREFBW */
					0x00000006 /* EMC_QUSE_EXTRA */
					0x00000004 /* EMC_FBIO_CFG6 */
					0x00000000 /* EMC_ODT_WRITE */
					0x00000000 /* EMC_ODT_READ */
					0x00004288 /* EMC_FBIO_CFG5 */
					0x004400a4 /* EMC_CFG_DIG_DLL */
					0x00008000 /* EMC_CFG_DIG_DLL_PERIOD */
					0x00080000 /* EMC_DLL_XFORM_DQS0 */
					0x00080000 /* EMC_DLL_XFORM_DQS1 */
					0x00080000 /* EMC_DLL_XFORM_DQS2 */
					0x00080000 /* EMC_DLL_XFORM_DQS3 */
					0x00080000 /* EMC_DLL_XFORM_DQS4 */
					0x00080000 /* EMC_DLL_XFORM_DQS5 */
					0x00080000 /* EMC_DLL_XFORM_DQS6 */
					0x00080000 /* EMC_DLL_XFORM_DQS7 */
					0x00000000 /* EMC_DLL_XFORM_QUSE0 */
					0x00000000 /* EMC_DLL_XFORM_QUSE1 */
					0x00000000 /* EMC_DLL_XFORM_QUSE2 */
					0x00000000 /* EMC_DLL_XFORM_QUSE3 */
					0x00000000 /* EMC_DLL_XFORM_QUSE4 */
					0x00000000 /* EMC_DLL_XFORM_QUSE5 */
					0x00000000 /* EMC_DLL_XFORM_QUSE6 */
					0x00000000 /* EMC_DLL_XFORM_QUSE7 */
					0x00000000 /* EMC_DLI_TRIM_TXDQS0 */
					0x00000000 /* EMC_DLI_TRIM_TXDQS1 */
					0x00000000 /* EMC_DLI_TRIM_TXDQS2 */
					0x00000000 /* EMC_DLI_TRIM_TXDQS3 */
					0x00000000 /* EMC_DLI_TRIM_TXDQS4 */
					0x00000000 /* EMC_DLI_TRIM_TXDQS5 */
					0x00000000 /* EMC_DLI_TRIM_TXDQS6 */
					0x00000000 /* EMC_DLI_TRIM_TXDQS7 */
					0x00080000 /* EMC_DLL_XFORM_DQ0 */
					0x00080000 /* EMC_DLL_XFORM_DQ1 */
					0x00080000 /* EMC_DLL_XFORM_DQ2 */
					0x00080000 /* EMC_DLL_XFORM_DQ3 */
					0x000002a0 /* EMC_XM2CMDPADCTRL */
					0x0800211c /* EMC_XM2DQSPADCTRL2 */
					0x00000000 /* EMC_XM2DQPADCTRL2 */
					0x77fff884 /* EMC_XM2CLKPADCTRL */
					0x01f1f108 /* EMC_XM2COMPPADCTRL */
					0x05057404 /* EMC_XM2VTTGENPADCTRL */
					0x54000007 /* EMC_XM2VTTGENPADCTRL2 */
					0x08000168 /* EMC_XM2QUSEPADCTRL */
					0x08000000 /* EMC_XM2DQSPADCTRL3 */
					0x00000802 /* EMC_CTT_TERM_CTRL */
					0x00020000 /* EMC_ZCAL_INTERVAL */
					0x00000100 /* EMC_ZCAL_WAIT_CNT */
					0x000c000c /* EMC_MRS_WAIT_CNT */
					0xa0f10000 /* EMC_AUTO_CAL_CONFIG */
					0x00000000 /* EMC_CTT */
					0x00000000 /* EMC_CTT_DURATION */
					0x80000d22 /* EMC_DYN_SELF_REF_CONTROL */
					0xe8000000 /* EMC_FBIO_SPARE */
					0xff00ff00 /* EMC_CFG_RSV */
				>;
			};
			timing-375000000 {
				clock-frequency = <375000000>;
				nvidia,emc-auto-cal-interval = <0x001fffff>;
				nvidia,emc-mode-1 = <0x80100002>;
				nvidia,emc-mode-2 = <0x80200000>;
				nvidia,emc-mode-reset = <0x80000521>;
				nvidia,emc-zcal-cnt-long = <0x00000040>;
				nvidia,emc-configuration = <
					0x00000011 /* EMC_RC */
					0x00000060 /* EMC_RFC */
					0x0000000c /* EMC_RAS */
					0x00000004 /* EMC_RP */
					0x00000003 /* EMC_R2W */
					0x00000008 /* EMC_W2R */
					0x00000002 /* EMC_R2P */
					0x0000000a /* EMC_W2P */
					0x00000004 /* EMC_RD_RCD */
					0x00000004 /* EMC_WR_RCD */
					0x00000002 /* EMC_RRD */
					0x00000001 /* EMC_REXT */
					0x00000000 /* EMC_WEXT */
					0x00000004 /* EMC_WDV */
					0x00000006 /* EMC_QUSE */
					0x00000004 /* EMC_QRST */
					0x0000000a /* EMC_QSAFE */
					0x0000000c /* EMC_RDV */
					0x00000b2d /* EMC_REFRESH */
					0x00000000 /* EMC_BURST_REFRESH_NUM */
					0x000002cb /* EMC_PRE_REFRESH_REQ_CNT */
					0x00000001 /* EMC_PDEX2WR */
					0x00000008 /* EMC_PDEX2RD */
					0x00000001 /* EMC_PCHG2PDEN */
					0x00000000 /* EMC_ACT2PDEN */
					0x00000007 /* EMC_AR2PDEN */
					0x0000000f /* EMC_RW2PDEN */
					0x00000066 /* EMC_TXSR */
					0x00000200 /* EMC_TXSRDLL */
					0x00000004 /* EMC_TCKE */
					0x0000000c /* EMC_TFAW */
					0x00000000 /* EMC_TRPAB */
					0x00000004 /* EMC_TCLKSTABLE */
					0x00000005 /* EMC_TCLKSTOP */
					0x00000b6d /* EMC_TREFBW */
					0x00000000 /* EMC_QUSE_EXTRA */
					0x00000004 /* EMC_FBIO_CFG6 */
					0x00000000 /* EMC_ODT_WRITE */
					0x00000000 /* EMC_ODT_READ */
					0x00007088 /* EMC_FBIO_CFG5 */
					0x00200084 /* EMC_CFG_DIG_DLL */
					0x00008000 /* EMC_CFG_DIG_DLL_PERIOD */
					0x00044000 /* EMC_DLL_XFORM_DQS0 */
					0x00044000 /* EMC_DLL_XFORM_DQS1 */
					0x00044000 /* EMC_DLL_XFORM_DQS2 */
					0x00044000 /* EMC_DLL_XFORM_DQS3 */
					0x00044000 /* EMC_DLL_XFORM_DQS4 */
					0x00044000 /* EMC_DLL_XFORM_DQS5 */
					0x00044000 /* EMC_DLL_XFORM_DQS6 */
					0x00044000 /* EMC_DLL_XFORM_DQS7 */
					0x00000000 /* EMC_DLL_XFORM_QUSE0 */
					0x00000000 /* EMC_DLL_XFORM_QUSE1 */
					0x00000000 /* EMC_DLL_XFORM_QUSE2 */
					0x00000000 /* EMC_DLL_XFORM_QUSE3 */
					0x00000000 /* EMC_DLL_XFORM_QUSE4 */
					0x00000000 /* EMC_DLL_XFORM_QUSE5 */
					0x00000000 /* EMC_DLL_XFORM_QUSE6 */
					0x00000000 /* EMC_DLL_XFORM_QUSE7 */
					0x00000000 /* EMC_DLI_TRIM_TXDQS0 */
					0x00000000 /* EMC_DLI_TRIM_TXDQS1 */
					0x00000000 /* EMC_DLI_TRIM_TXDQS2 */
					0x00000000 /* EMC_DLI_TRIM_TXDQS3 */
					0x00000000 /* EMC_DLI_TRIM_TXDQS4 */
					0x00000000 /* EMC_DLI_TRIM_TXDQS5 */
					0x00000000 /* EMC_DLI_TRIM_TXDQS6 */
					0x00000000 /* EMC_DLI_TRIM_TXDQS7 */
					0x00058000 /* EMC_DLL_XFORM_DQ0 */
					0x00058000 /* EMC_DLL_XFORM_DQ1 */
					0x00058000 /* EMC_DLL_XFORM_DQ2 */
					0x00058000 /* EMC_DLL_XFORM_DQ3 */
					0x000002a0 /* EMC_XM2CMDPADCTRL */
					0x0800013d /* EMC_XM2DQSPADCTRL2 */
					0x00000000 /* EMC_XM2DQPADCTRL2 */
					0x77fff884 /* EMC_XM2CLKPADCTRL */
					0x01f1f508 /* EMC_XM2COMPPADCTRL */
					0x05057404 /* EMC_XM2VTTGENPADCTRL */
					0x54000007 /* EMC_XM2VTTGENPADCTRL2 */
					0x080001e8 /* EMC_XM2QUSEPADCTRL */
					0x08000021 /* EMC_XM2DQSPADCTRL3 */
					0x00000802 /* EMC_CTT_TERM_CTRL */
					0x00020000 /* EMC_ZCAL_INTERVAL */
					0x00000100 /* EMC_ZCAL_WAIT_CNT */
					0x015f000c /* EMC_MRS_WAIT_CNT */
					0xa0f10000 /* EMC_AUTO_CAL_CONFIG */
					0x00000000 /* EMC_CTT */
					0x00000000 /* EMC_CTT_DURATION */
					0x8000174b /* EMC_DYN_SELF_REF_CONTROL */
					0xe8000000 /* EMC_FBIO_SPARE */
					0xff00ff89 /* EMC_CFG_RSV */
				>;
			};
			timing-750000000 {
				clock-frequency = <750000000>;
				nvidia,emc-auto-cal-interval = <0x001fffff>;
				nvidia,emc-mode-1 = <0x80100002>;
				nvidia,emc-mode-2 = <0x80200018>;
				nvidia,emc-mode-reset = <0x80000d71>;
				nvidia,emc-zcal-cnt-long = <0x00000040>;
				nvidia,emc-cfg-periodic-qrst;
				nvidia,emc-configuration = <
					0x00000023 /* EMC_RC */
					0x000000c1 /* EMC_RFC */
					0x00000019 /* EMC_RAS */
					0x00000009 /* EMC_RP */
					0x00000005 /* EMC_R2W */
					0x0000000d /* EMC_W2R */
					0x00000004 /* EMC_R2P */
					0x00000013 /* EMC_W2P */
					0x00000009 /* EMC_RD_RCD */
					0x00000009 /* EMC_WR_RCD */
					0x00000003 /* EMC_RRD */
					0x00000001 /* EMC_REXT */
					0x00000000 /* EMC_WEXT */
					0x00000007 /* EMC_WDV */
					0x0000000b /* EMC_QUSE */
					0x00000009 /* EMC_QRST */
					0x0000000c /* EMC_QSAFE */
					0x00000011 /* EMC_RDV */
					0x0000169a /* EMC_REFRESH */
					0x00000000 /* EMC_BURST_REFRESH_NUM */
					0x000005a6 /* EMC_PRE_REFRESH_REQ_CNT */
					0x00000003 /* EMC_PDEX2WR */
					0x00000010 /* EMC_PDEX2RD */
					0x00000001 /* EMC_PCHG2PDEN */
					0x00000000 /* EMC_ACT2PDEN */
					0x0000000e /* EMC_AR2PDEN */
					0x00000018 /* EMC_RW2PDEN */
					0x000000cb /* EMC_TXSR */
					0x00000200 /* EMC_TXSRDLL */
					0x00000005 /* EMC_TCKE */
					0x00000017 /* EMC_TFAW */
					0x00000000 /* EMC_TRPAB */
					0x00000007 /* EMC_TCLKSTABLE */
					0x00000008 /* EMC_TCLKSTOP */
					0x000016da /* EMC_TREFBW */
					0x0000000c /* EMC_QUSE_EXTRA */
					0x00000004 /* EMC_FBIO_CFG6 */
					0x00000000 /* EMC_ODT_WRITE */
					0x00000000 /* EMC_ODT_READ */
					0x00005088 /* EMC_FBIO_CFG5 */
					0xf0080191 /* EMC_CFG_DIG_DLL */
					0x00008000 /* EMC_CFG_DIG_DLL_PERIOD */
					0x0000000c /* EMC_DLL_XFORM_DQS0 */
					0x0000000c /* EMC_DLL_XFORM_DQS1 */
					0x0000000c /* EMC_DLL_XFORM_DQS2 */
					0x0000000c /* EMC_DLL_XFORM_DQS3 */
					0x00000006 /* EMC_DLL_XFORM_DQS4 */
					0x00000006 /* EMC_DLL_XFORM_DQS5 */
					0x00000006 /* EMC_DLL_XFORM_DQS6 */
					0x00000006 /* EMC_DLL_XFORM_DQS7 */
					0x00000000 /* EMC_DLL_XFORM_QUSE0 */
					0x00000000 /* EMC_DLL_XFORM_QUSE1 */
					0x00000000 /* EMC_DLL_XFORM_QUSE2 */
					0x00000000 /* EMC_DLL_XFORM_QUSE3 */
					0x00000000 /* EMC_DLL_XFORM_QUSE4 */
					0x00000000 /* EMC_DLL_XFORM_QUSE5 */
					0x00000000 /* EMC_DLL_XFORM_QUSE6 */
					0x00000000 /* EMC_DLL_XFORM_QUSE7 */
					0x00000000 /* EMC_DLI_TRIM_TXDQS0 */
					0x00000000 /* EMC_DLI_TRIM_TXDQS1 */
					0x00000000 /* EMC_DLI_TRIM_TXDQS2 */
					0x00000000 /* EMC_DLI_TRIM_TXDQS3 */
					0x00000000 /* EMC_DLI_TRIM_TXDQS4 */
					0x00000000 /* EMC_DLI_TRIM_TXDQS5 */
					0x00000000 /* EMC_DLI_TRIM_TXDQS6 */
					0x00000000 /* EMC_DLI_TRIM_TXDQS7 */
					0x0000000e /* EMC_DLL_XFORM_DQ0 */
					0x0000000e /* EMC_DLL_XFORM_DQ1 */
					0x0000000e /* EMC_DLL_XFORM_DQ2 */
					0x0000000e /* EMC_DLL_XFORM_DQ3 */
					0x000002a0 /* EMC_XM2CMDPADCTRL */
					0x0800013d /* EMC_XM2DQSPADCTRL2 */
					0x22220000 /* EMC_XM2DQPADCTRL2 */
					0x77fff884 /* EMC_XM2CLKPADCTRL */
					0x01f1f501 /* EMC_XM2COMPPADCTRL */
					0x07077404 /* EMC_XM2VTTGENPADCTRL */
					0x54000000 /* EMC_XM2VTTGENPADCTRL2 */
					0x080001e8 /* EMC_XM2QUSEPADCTRL */
					0x08000021 /* EMC_XM2DQSPADCTRL3 */
					0x00000802 /* EMC_CTT_TERM_CTRL */
					0x00020000 /* EMC_ZCAL_INTERVAL */
					0x00000100 /* EMC_ZCAL_WAIT_CNT */
					0x00fd000c /* EMC_MRS_WAIT_CNT */
					0xa0f10404 /* EMC_AUTO_CAL_CONFIG */
					0x00000000 /* EMC_CTT */
					0x00000000 /* EMC_CTT_DURATION */
					0x80002d93 /* EMC_DYN_SELF_REF_CONTROL */
					0xf8000000 /* EMC_FBIO_SPARE */
					0xff00ff49 /* EMC_CFG_RSV */
				>;
			};
		};
		emc-timings-1 {
			nvidia,ram-code = <1>;
			timing-51000000 {
				clock-frequency = <51000000>;
				nvidia,emc-auto-cal-interval = <0x001fffff>;
				nvidia,emc-mode-1 = <0x80100003>;
				nvidia,emc-mode-2 = <0x80200008>;
				nvidia,emc-mode-reset = <0x80001221>;
				nvidia,emc-zcal-cnt-long = <0x00000040>;
				nvidia,emc-cfg-periodic-qrst;
				nvidia,emc-cfg-dyn-self-ref;
				nvidia,emc-configuration = <
					0x00000002 /* EMC_RC */
					0x0000000d /* EMC_RFC */
					0x00000001 /* EMC_RAS */
					0x00000000 /* EMC_RP */
					0x00000002 /* EMC_R2W */
					0x0000000a /* EMC_W2R */
					0x00000005 /* EMC_R2P */
					0x0000000b /* EMC_W2P */
					0x00000000 /* EMC_RD_RCD */
					0x00000000 /* EMC_WR_RCD */
					0x00000003 /* EMC_RRD */
					0x00000001 /* EMC_REXT */
					0x00000000 /* EMC_WEXT */
					0x00000005 /* EMC_WDV */
					0x00000005 /* EMC_QUSE */
					0x00000004 /* EMC_QRST */
					0x0000000a /* EMC_QSAFE */
					0x0000000b /* EMC_RDV */
					0x00000181 /* EMC_REFRESH */
					0x00000000 /* EMC_BURST_REFRESH_NUM */
					0x00000060 /* EMC_PRE_REFRESH_REQ_CNT */
					0x00000002 /* EMC_PDEX2WR */
					0x00000002 /* EMC_PDEX2RD */
					0x00000001 /* EMC_PCHG2PDEN */
					0x00000000 /* EMC_ACT2PDEN */
					0x00000007 /* EMC_AR2PDEN */
					0x0000000f /* EMC_RW2PDEN */
					0x0000000e /* EMC_TXSR */
					0x0000000e /* EMC_TXSRDLL */
					0x00000004 /* EMC_TCKE */
					0x00000002 /* EMC_TFAW */
					0x00000000 /* EMC_TRPAB */
					0x00000004 /* EMC_TCLKSTABLE */
					0x00000005 /* EMC_TCLKSTOP */
					0x0000018e /* EMC_TREFBW */
					0x00000006 /* EMC_QUSE_EXTRA */
					0x00000004 /* EMC_FBIO_CFG6 */
					0x00000000 /* EMC_ODT_WRITE */
					0x00000000 /* EMC_ODT_READ */
					0x00004288 /* EMC_FBIO_CFG5 */
					0x007800a4 /* EMC_CFG_DIG_DLL */
					0x00008000 /* EMC_CFG_DIG_DLL_PERIOD */
					0x000fc000 /* EMC_DLL_XFORM_DQS0 */
					0x000fc000 /* EMC_DLL_XFORM_DQS1 */
					0x000fc000 /* EMC_DLL_XFORM_DQS2 */
					0x000fc000 /* EMC_DLL_XFORM_DQS3 */
					0x000fc000 /* EMC_DLL_XFORM_DQS4 */
					0x000fc000 /* EMC_DLL_XFORM_DQS5 */
					0x000fc000 /* EMC_DLL_XFORM_DQS6 */
					0x000fc000 /* EMC_DLL_XFORM_DQS7 */
					0x00000000 /* EMC_DLL_XFORM_QUSE0 */
					0x00000000 /* EMC_DLL_XFORM_QUSE1 */
					0x00000000 /* EMC_DLL_XFORM_QUSE2 */
					0x00000000 /* EMC_DLL_XFORM_QUSE3 */
					0x00000000 /* EMC_DLL_XFORM_QUSE4 */
					0x00000000 /* EMC_DLL_XFORM_QUSE5 */
					0x00000000 /* EMC_DLL_XFORM_QUSE6 */
					0x00000000 /* EMC_DLL_XFORM_QUSE7 */
					0x00000000 /* EMC_DLI_TRIM_TXDQS0 */
					0x00000000 /* EMC_DLI_TRIM_TXDQS1 */
					0x00000000 /* EMC_DLI_TRIM_TXDQS2 */
					0x00000000 /* EMC_DLI_TRIM_TXDQS3 */
					0x00000000 /* EMC_DLI_TRIM_TXDQS4 */
					0x00000000 /* EMC_DLI_TRIM_TXDQS5 */
					0x00000000 /* EMC_DLI_TRIM_TXDQS6 */
					0x00000000 /* EMC_DLI_TRIM_TXDQS7 */
					0x000fc000 /* EMC_DLL_XFORM_DQ0 */
					0x000fc000 /* EMC_DLL_XFORM_DQ1 */
					0x000fc000 /* EMC_DLL_XFORM_DQ2 */
					0x000fc000 /* EMC_DLL_XFORM_DQ3 */
					0x000002a0 /* EMC_XM2CMDPADCTRL */
					0x0800211c /* EMC_XM2DQSPADCTRL2 */
					0x00000000 /* EMC_XM2DQPADCTRL2 */
					0x77fff884 /* EMC_XM2CLKPADCTRL */
					0x01f1f108 /* EMC_XM2COMPPADCTRL */
					0x05057404 /* EMC_XM2VTTGENPADCTRL */
					0x54000007 /* EMC_XM2VTTGENPADCTRL2 */
					0x08000168 /* EMC_XM2QUSEPADCTRL */
					0x08000000 /* EMC_XM2DQSPADCTRL3 */
					0x00000802 /* EMC_CTT_TERM_CTRL */
					0x00000000 /* EMC_ZCAL_INTERVAL */
					0x00000040 /* EMC_ZCAL_WAIT_CNT */
					0x000c000c /* EMC_MRS_WAIT_CNT */
					0xa0f10000 /* EMC_AUTO_CAL_CONFIG */
					0x00000000 /* EMC_CTT */
					0x00000000 /* EMC_CTT_DURATION */
					0x8000040b /* EMC_DYN_SELF_REF_CONTROL */
					0xe8000000 /* EMC_FBIO_SPARE */
					0xff00ff00 /* EMC_CFG_RSV */
				>;
			};
			timing-102000000 {
				clock-frequency = <102000000>;
				nvidia,emc-auto-cal-interval = <0x001fffff>;
				nvidia,emc-mode-1 = <0x80100003>;
				nvidia,emc-mode-2 = <0x80200008>;
				nvidia,emc-mode-reset = <0x80001221>;
				nvidia,emc-zcal-cnt-long = <0x00000040>;
				nvidia,emc-cfg-periodic-qrst;
				nvidia,emc-cfg-dyn-self-ref;
				nvidia,emc-configuration = <
					0x00000004 /* EMC_RC */
					0x0000001a /* EMC_RFC */
					0x00000003 /* EMC_RAS */
					0x00000001 /* EMC_RP */
					0x00000002 /* EMC_R2W */
					0x0000000a /* EMC_W2R */
					0x00000005 /* EMC_R2P */
					0x0000000b /* EMC_W2P */
					0x00000001 /* EMC_RD_RCD */
					0x00000001 /* EMC_WR_RCD */
					0x00000003 /* EMC_RRD */
					0x00000001 /* EMC_REXT */
					0x00000000 /* EMC_WEXT */
					0x00000005 /* EMC_WDV */
					0x00000005 /* EMC_QUSE */
					0x00000004 /* EMC_QRST */
					0x0000000a /* EMC_QSAFE */
					0x0000000b /* EMC_RDV */
					0x00000303 /* EMC_REFRESH */
					0x00000000 /* EMC_BURST_REFRESH_NUM */
					0x000000c0 /* EMC_PRE_REFRESH_REQ_CNT */
					0x00000002 /* EMC_PDEX2WR */
					0x00000002 /* EMC_PDEX2RD */
					0x00000001 /* EMC_PCHG2PDEN */
					0x00000000 /* EMC_ACT2PDEN */
					0x00000007 /* EMC_AR2PDEN */
					0x0000000f /* EMC_RW2PDEN */
					0x0000001c /* EMC_TXSR */
					0x0000001c /* EMC_TXSRDLL */
					0x00000004 /* EMC_TCKE */
					0x00000004 /* EMC_TFAW */
					0x00000000 /* EMC_TRPAB */
					0x00000004 /* EMC_TCLKSTABLE */
					0x00000005 /* EMC_TCLKSTOP */
					0x0000031c /* EMC_TREFBW */
					0x00000006 /* EMC_QUSE_EXTRA */
					0x00000004 /* EMC_FBIO_CFG6 */
					0x00000000 /* EMC_ODT_WRITE */
					0x00000000 /* EMC_ODT_READ */
					0x00004288 /* EMC_FBIO_CFG5 */
					0x007800a4 /* EMC_CFG_DIG_DLL */
					0x00008000 /* EMC_CFG_DIG_DLL_PERIOD */
					0x000fc000 /* EMC_DLL_XFORM_DQS0 */
					0x000fc000 /* EMC_DLL_XFORM_DQS1 */
					0x000fc000 /* EMC_DLL_XFORM_DQS2 */
					0x000fc000 /* EMC_DLL_XFORM_DQS3 */
					0x000fc000 /* EMC_DLL_XFORM_DQS4 */
					0x000fc000 /* EMC_DLL_XFORM_DQS5 */
					0x000fc000 /* EMC_DLL_XFORM_DQS6 */
					0x000fc000 /* EMC_DLL_XFORM_DQS7 */
					0x00000000 /* EMC_DLL_XFORM_QUSE0 */
					0x00000000 /* EMC_DLL_XFORM_QUSE1 */
					0x00000000 /* EMC_DLL_XFORM_QUSE2 */
					0x00000000 /* EMC_DLL_XFORM_QUSE3 */
					0x00000000 /* EMC_DLL_XFORM_QUSE4 */
					0x00000000 /* EMC_DLL_XFORM_QUSE5 */
					0x00000000 /* EMC_DLL_XFORM_QUSE6 */
					0x00000000 /* EMC_DLL_XFORM_QUSE7 */
					0x00000000 /* EMC_DLI_TRIM_TXDQS0 */
					0x00000000 /* EMC_DLI_TRIM_TXDQS1 */
					0x00000000 /* EMC_DLI_TRIM_TXDQS2 */
					0x00000000 /* EMC_DLI_TRIM_TXDQS3 */
					0x00000000 /* EMC_DLI_TRIM_TXDQS4 */
					0x00000000 /* EMC_DLI_TRIM_TXDQS5 */
					0x00000000 /* EMC_DLI_TRIM_TXDQS6 */
					0x00000000 /* EMC_DLI_TRIM_TXDQS7 */
					0x000fc000 /* EMC_DLL_XFORM_DQ0 */
					0x000fc000 /* EMC_DLL_XFORM_DQ1 */
					0x000fc000 /* EMC_DLL_XFORM_DQ2 */
					0x000fc000 /* EMC_DLL_XFORM_DQ3 */
					0x000002a0 /* EMC_XM2CMDPADCTRL */
					0x0800211c /* EMC_XM2DQSPADCTRL2 */
					0x00000000 /* EMC_XM2DQPADCTRL2 */
					0x77fff884 /* EMC_XM2CLKPADCTRL */
					0x01f1f108 /* EMC_XM2COMPPADCTRL */
					0x05057404 /* EMC_XM2VTTGENPADCTRL */
					0x54000007 /* EMC_XM2VTTGENPADCTRL2 */
					0x08000168 /* EMC_XM2QUSEPADCTRL */
					0x08000000 /* EMC_XM2DQSPADCTRL3 */
					0x00000802 /* EMC_CTT_TERM_CTRL */
					0x00000000 /* EMC_ZCAL_INTERVAL */
					0x00000040 /* EMC_ZCAL_WAIT_CNT */
					0x000c000c /* EMC_MRS_WAIT_CNT */
					0xa0f10000 /* EMC_AUTO_CAL_CONFIG */
					0x00000000 /* EMC_CTT */
					0x00000000 /* EMC_CTT_DURATION */
					0x80000713 /* EMC_DYN_SELF_REF_CONTROL */
					0xe8000000 /* EMC_FBIO_SPARE */
					0xff00ff00 /* EMC_CFG_RSV */
				>;
			};
			timing-204000000 {
				clock-frequency = <204000000>;
				nvidia,emc-auto-cal-interval = <0x001fffff>;
				nvidia,emc-mode-1 = <0x80100003>;
				nvidia,emc-mode-2 = <0x80200008>;
				nvidia,emc-mode-reset = <0x80001221>;
				nvidia,emc-zcal-cnt-long = <0x00000040>;
				nvidia,emc-cfg-periodic-qrst;
				nvidia,emc-cfg-dyn-self-ref;
				nvidia,emc-configuration = <
					0x00000009 /* EMC_RC */
					0x00000035 /* EMC_RFC */
					0x00000007 /* EMC_RAS */
					0x00000002 /* EMC_RP */
					0x00000002 /* EMC_R2W */
					0x0000000a /* EMC_W2R */
					0x00000005 /* EMC_R2P */
					0x0000000b /* EMC_W2P */
					0x00000002 /* EMC_RD_RCD */
					0x00000002 /* EMC_WR_RCD */
					0x00000003 /* EMC_RRD */
					0x00000001 /* EMC_REXT */
					0x00000000 /* EMC_WEXT */
					0x00000005 /* EMC_WDV */
					0x00000005 /* EMC_QUSE */
					0x00000004 /* EMC_QRST */
					0x0000000a /* EMC_QSAFE */
					0x0000000b /* EMC_RDV */
					0x00000607 /* EMC_REFRESH */
					0x00000000 /* EMC_BURST_REFRESH_NUM */
					0x00000181 /* EMC_PRE_REFRESH_REQ_CNT */
					0x00000002 /* EMC_PDEX2WR */
					0x00000002 /* EMC_PDEX2RD */
					0x00000001 /* EMC_PCHG2PDEN */
					0x00000000 /* EMC_ACT2PDEN */
					0x00000007 /* EMC_AR2PDEN */
					0x0000000f /* EMC_RW2PDEN */
					0x00000038 /* EMC_TXSR */
					0x00000038 /* EMC_TXSRDLL */
					0x00000004 /* EMC_TCKE */
					0x00000007 /* EMC_TFAW */
					0x00000000 /* EMC_TRPAB */
					0x00000004 /* EMC_TCLKSTABLE */
					0x00000005 /* EMC_TCLKSTOP */
					0x00000638 /* EMC_TREFBW */
					0x00000006 /* EMC_QUSE_EXTRA */
					0x00000004 /* EMC_FBIO_CFG6 */
					0x00000000 /* EMC_ODT_WRITE */
					0x00000000 /* EMC_ODT_READ */
					0x00004288 /* EMC_FBIO_CFG5 */
					0x004400a4 /* EMC_CFG_DIG_DLL */
					0x00008000 /* EMC_CFG_DIG_DLL_PERIOD */
					0x00080000 /* EMC_DLL_XFORM_DQS0 */
					0x00080000 /* EMC_DLL_XFORM_DQS1 */
					0x00080000 /* EMC_DLL_XFORM_DQS2 */
					0x00080000 /* EMC_DLL_XFORM_DQS3 */
					0x00080000 /* EMC_DLL_XFORM_DQS4 */
					0x00080000 /* EMC_DLL_XFORM_DQS5 */
					0x00080000 /* EMC_DLL_XFORM_DQS6 */
					0x00080000 /* EMC_DLL_XFORM_DQS7 */
					0x00000000 /* EMC_DLL_XFORM_QUSE0 */
					0x00000000 /* EMC_DLL_XFORM_QUSE1 */
					0x00000000 /* EMC_DLL_XFORM_QUSE2 */
					0x00000000 /* EMC_DLL_XFORM_QUSE3 */
					0x00000000 /* EMC_DLL_XFORM_QUSE4 */
					0x00000000 /* EMC_DLL_XFORM_QUSE5 */
					0x00000000 /* EMC_DLL_XFORM_QUSE6 */
					0x00000000 /* EMC_DLL_XFORM_QUSE7 */
					0x00000000 /* EMC_DLI_TRIM_TXDQS0 */
					0x00000000 /* EMC_DLI_TRIM_TXDQS1 */
					0x00000000 /* EMC_DLI_TRIM_TXDQS2 */
					0x00000000 /* EMC_DLI_TRIM_TXDQS3 */
					0x00000000 /* EMC_DLI_TRIM_TXDQS4 */
					0x00000000 /* EMC_DLI_TRIM_TXDQS5 */
					0x00000000 /* EMC_DLI_TRIM_TXDQS6 */
					0x00000000 /* EMC_DLI_TRIM_TXDQS7 */
					0x00080000 /* EMC_DLL_XFORM_DQ0 */
					0x00080000 /* EMC_DLL_XFORM_DQ1 */
					0x00080000 /* EMC_DLL_XFORM_DQ2 */
					0x00080000 /* EMC_DLL_XFORM_DQ3 */
					0x000002a0 /* EMC_XM2CMDPADCTRL */
					0x0800211c /* EMC_XM2DQSPADCTRL2 */
					0x00000000 /* EMC_XM2DQPADCTRL2 */
					0x77fff884 /* EMC_XM2CLKPADCTRL */
					0x01f1f108 /* EMC_XM2COMPPADCTRL */
					0x05057404 /* EMC_XM2VTTGENPADCTRL */
					0x54000007 /* EMC_XM2VTTGENPADCTRL2 */
					0x08000168 /* EMC_XM2QUSEPADCTRL */
					0x08000000 /* EMC_XM2DQSPADCTRL3 */
					0x00000802 /* EMC_CTT_TERM_CTRL */
					0x00020000 /* EMC_ZCAL_INTERVAL */
					0x00000100 /* EMC_ZCAL_WAIT_CNT */
					0x000c000c /* EMC_MRS_WAIT_CNT */
					0xa0f10000 /* EMC_AUTO_CAL_CONFIG */
					0x00000000 /* EMC_CTT */
					0x00000000 /* EMC_CTT_DURATION */
					0x80000d22 /* EMC_DYN_SELF_REF_CONTROL */
					0xe8000000 /* EMC_FBIO_SPARE */
					0xff00ff00 /* EMC_CFG_RSV */
				>;
			};
			timing-375000000 {
				clock-frequency = <375000000>;
				nvidia,emc-auto-cal-interval = <0x001fffff>;
				nvidia,emc-mode-1 = <0x80100002>;
				nvidia,emc-mode-2 = <0x80200000>;
				nvidia,emc-mode-reset = <0x80000521>;
				nvidia,emc-zcal-cnt-long = <0x00000040>;
				nvidia,emc-configuration = <
					0x00000011 /* EMC_RC */
					0x00000060 /* EMC_RFC */
					0x0000000c /* EMC_RAS */
					0x00000004 /* EMC_RP */
					0x00000003 /* EMC_R2W */
					0x00000008 /* EMC_W2R */
					0x00000002 /* EMC_R2P */
					0x0000000a /* EMC_W2P */
					0x00000004 /* EMC_RD_RCD */
					0x00000004 /* EMC_WR_RCD */
					0x00000002 /* EMC_RRD */
					0x00000001 /* EMC_REXT */
					0x00000000 /* EMC_WEXT */
					0x00000004 /* EMC_WDV */
					0x00000006 /* EMC_QUSE */
					0x00000004 /* EMC_QRST */
					0x0000000a /* EMC_QSAFE */
					0x0000000c /* EMC_RDV */
					0x00000b2d /* EMC_REFRESH */
					0x00000000 /* EMC_BURST_REFRESH_NUM */
					0x000002cb /* EMC_PRE_REFRESH_REQ_CNT */
					0x00000001 /* EMC_PDEX2WR */
					0x00000008 /* EMC_PDEX2RD */
					0x00000001 /* EMC_PCHG2PDEN */
					0x00000000 /* EMC_ACT2PDEN */
					0x00000007 /* EMC_AR2PDEN */
					0x0000000f /* EMC_RW2PDEN */
					0x00000066 /* EMC_TXSR */
					0x00000200 /* EMC_TXSRDLL */
					0x00000004 /* EMC_TCKE */
					0x0000000c /* EMC_TFAW */
					0x00000000 /* EMC_TRPAB */
					0x00000004 /* EMC_TCLKSTABLE */
					0x00000005 /* EMC_TCLKSTOP */
					0x00000b6d /* EMC_TREFBW */
					0x00000000 /* EMC_QUSE_EXTRA */
					0x00000004 /* EMC_FBIO_CFG6 */
					0x00000000 /* EMC_ODT_WRITE */
					0x00000000 /* EMC_ODT_READ */
					0x00007088 /* EMC_FBIO_CFG5 */
					0x00200084 /* EMC_CFG_DIG_DLL */
					0x00008000 /* EMC_CFG_DIG_DLL_PERIOD */
					0x00044000 /* EMC_DLL_XFORM_DQS0 */
					0x00044000 /* EMC_DLL_XFORM_DQS1 */
					0x00044000 /* EMC_DLL_XFORM_DQS2 */
					0x00044000 /* EMC_DLL_XFORM_DQS3 */
					0x00044000 /* EMC_DLL_XFORM_DQS4 */
					0x00044000 /* EMC_DLL_XFORM_DQS5 */
					0x00044000 /* EMC_DLL_XFORM_DQS6 */
					0x00044000 /* EMC_DLL_XFORM_DQS7 */
					0x00000000 /* EMC_DLL_XFORM_QUSE0 */
					0x00000000 /* EMC_DLL_XFORM_QUSE1 */
					0x00000000 /* EMC_DLL_XFORM_QUSE2 */
					0x00000000 /* EMC_DLL_XFORM_QUSE3 */
					0x00000000 /* EMC_DLL_XFORM_QUSE4 */
					0x00000000 /* EMC_DLL_XFORM_QUSE5 */
					0x00000000 /* EMC_DLL_XFORM_QUSE6 */
					0x00000000 /* EMC_DLL_XFORM_QUSE7 */
					0x00000000 /* EMC_DLI_TRIM_TXDQS0 */
					0x00000000 /* EMC_DLI_TRIM_TXDQS1 */
					0x00000000 /* EMC_DLI_TRIM_TXDQS2 */
					0x00000000 /* EMC_DLI_TRIM_TXDQS3 */
					0x00000000 /* EMC_DLI_TRIM_TXDQS4 */
					0x00000000 /* EMC_DLI_TRIM_TXDQS5 */
					0x00000000 /* EMC_DLI_TRIM_TXDQS6 */
					0x00000000 /* EMC_DLI_TRIM_TXDQS7 */
					0x00058000 /* EMC_DLL_XFORM_DQ0 */
					0x00058000 /* EMC_DLL_XFORM_DQ1 */
					0x00058000 /* EMC_DLL_XFORM_DQ2 */
					0x00058000 /* EMC_DLL_XFORM_DQ3 */
					0x000002a0 /* EMC_XM2CMDPADCTRL */
					0x0800013d /* EMC_XM2DQSPADCTRL2 */
					0x00000000 /* EMC_XM2DQPADCTRL2 */
					0x77fff884 /* EMC_XM2CLKPADCTRL */
					0x01f1f508 /* EMC_XM2COMPPADCTRL */
					0x05057404 /* EMC_XM2VTTGENPADCTRL */
					0x54000007 /* EMC_XM2VTTGENPADCTRL2 */
					0x080001e8 /* EMC_XM2QUSEPADCTRL */
					0x08000021 /* EMC_XM2DQSPADCTRL3 */
					0x00000802 /* EMC_CTT_TERM_CTRL */
					0x00020000 /* EMC_ZCAL_INTERVAL */
					0x00000100 /* EMC_ZCAL_WAIT_CNT */
					0x015f000c /* EMC_MRS_WAIT_CNT */
					0xa0f10000 /* EMC_AUTO_CAL_CONFIG */
					0x00000000 /* EMC_CTT */
					0x00000000 /* EMC_CTT_DURATION */
					0x8000174b /* EMC_DYN_SELF_REF_CONTROL */
					0xe8000000 /* EMC_FBIO_SPARE */
					0xff00ff89 /* EMC_CFG_RSV */
				>;
			};
			timing-750000000 {
				clock-frequency = <750000000>;
				nvidia,emc-auto-cal-interval = <0x001fffff>;
				nvidia,emc-mode-1 = <0x80100002>;
				nvidia,emc-mode-2 = <0x80200018>;
				nvidia,emc-mode-reset = <0x80000d71>;
				nvidia,emc-zcal-cnt-long = <0x00000040>;
				nvidia,emc-cfg-periodic-qrst;
				nvidia,emc-configuration = <
					0x00000023 /* EMC_RC */
					0x000000c1 /* EMC_RFC */
					0x00000019 /* EMC_RAS */
					0x00000009 /* EMC_RP */
					0x00000005 /* EMC_R2W */
					0x0000000d /* EMC_W2R */
					0x00000004 /* EMC_R2P */
					0x00000013 /* EMC_W2P */
					0x00000009 /* EMC_RD_RCD */
					0x00000009 /* EMC_WR_RCD */
					0x00000003 /* EMC_RRD */
					0x00000001 /* EMC_REXT */
					0x00000000 /* EMC_WEXT */
					0x00000007 /* EMC_WDV */
					0x0000000b /* EMC_QUSE */
					0x00000009 /* EMC_QRST */
					0x0000000c /* EMC_QSAFE */
					0x00000011 /* EMC_RDV */
					0x0000169a /* EMC_REFRESH */
					0x00000000 /* EMC_BURST_REFRESH_NUM */
					0x000005a6 /* EMC_PRE_REFRESH_REQ_CNT */
					0x00000003 /* EMC_PDEX2WR */
					0x00000010 /* EMC_PDEX2RD */
					0x00000001 /* EMC_PCHG2PDEN */
					0x00000000 /* EMC_ACT2PDEN */
					0x0000000e /* EMC_AR2PDEN */
					0x00000018 /* EMC_RW2PDEN */
					0x000000cb /* EMC_TXSR */
					0x00000200 /* EMC_TXSRDLL */
					0x00000005 /* EMC_TCKE */
					0x00000017 /* EMC_TFAW */
					0x00000000 /* EMC_TRPAB */
					0x00000007 /* EMC_TCLKSTABLE */
					0x00000008 /* EMC_TCLKSTOP */
					0x000016da /* EMC_TREFBW */
					0x0000000c /* EMC_QUSE_EXTRA */
					0x00000004 /* EMC_FBIO_CFG6 */
					0x00000000 /* EMC_ODT_WRITE */
					0x00000000 /* EMC_ODT_READ */
					0x00005088 /* EMC_FBIO_CFG5 */
					0xf0080191 /* EMC_CFG_DIG_DLL */
					0x00008000 /* EMC_CFG_DIG_DLL_PERIOD */
					0x0000000c /* EMC_DLL_XFORM_DQS0 */
					0x0000000c /* EMC_DLL_XFORM_DQS1 */
					0x0000000c /* EMC_DLL_XFORM_DQS2 */
					0x0000000c /* EMC_DLL_XFORM_DQS3 */
					0x00000006 /* EMC_DLL_XFORM_DQS4 */
					0x00000006 /* EMC_DLL_XFORM_DQS5 */
					0x00000006 /* EMC_DLL_XFORM_DQS6 */
					0x00000006 /* EMC_DLL_XFORM_DQS7 */
					0x00000000 /* EMC_DLL_XFORM_QUSE0 */
					0x00000000 /* EMC_DLL_XFORM_QUSE1 */
					0x00000000 /* EMC_DLL_XFORM_QUSE2 */
					0x00000000 /* EMC_DLL_XFORM_QUSE3 */
					0x00000000 /* EMC_DLL_XFORM_QUSE4 */
					0x00000000 /* EMC_DLL_XFORM_QUSE5 */
					0x00000000 /* EMC_DLL_XFORM_QUSE6 */
					0x00000000 /* EMC_DLL_XFORM_QUSE7 */
					0x00000000 /* EMC_DLI_TRIM_TXDQS0 */
					0x00000000 /* EMC_DLI_TRIM_TXDQS1 */
					0x00000000 /* EMC_DLI_TRIM_TXDQS2 */
					0x00000000 /* EMC_DLI_TRIM_TXDQS3 */
					0x00000000 /* EMC_DLI_TRIM_TXDQS4 */
					0x00000000 /* EMC_DLI_TRIM_TXDQS5 */
					0x00000000 /* EMC_DLI_TRIM_TXDQS6 */
					0x00000000 /* EMC_DLI_TRIM_TXDQS7 */
					0x0000000e /* EMC_DLL_XFORM_DQ0 */
					0x0000000e /* EMC_DLL_XFORM_DQ1 */
					0x0000000e /* EMC_DLL_XFORM_DQ2 */
					0x0000000e /* EMC_DLL_XFORM_DQ3 */
					0x000002a0 /* EMC_XM2CMDPADCTRL */
					0x0800013d /* EMC_XM2DQSPADCTRL2 */
					0x22220000 /* EMC_XM2DQPADCTRL2 */
					0x77fff884 /* EMC_XM2CLKPADCTRL */
					0x01f1f501 /* EMC_XM2COMPPADCTRL */
					0x07077404 /* EMC_XM2VTTGENPADCTRL */
					0x54000000 /* EMC_XM2VTTGENPADCTRL2 */
					0x080001e8 /* EMC_XM2QUSEPADCTRL */
					0x08000021 /* EMC_XM2DQSPADCTRL3 */
					0x00000802 /* EMC_CTT_TERM_CTRL */
					0x00020000 /* EMC_ZCAL_INTERVAL */
					0x00000100 /* EMC_ZCAL_WAIT_CNT */
					0x00fd000c /* EMC_MRS_WAIT_CNT */
					0xa0f10404 /* EMC_AUTO_CAL_CONFIG */
					0x00000000 /* EMC_CTT */
					0x00000000 /* EMC_CTT_DURATION */
					0x80002d93 /* EMC_DYN_SELF_REF_CONTROL */
					0xf8000000 /* EMC_FBIO_SPARE */
					0xff00ff49 /* EMC_CFG_RSV */
				>;
			};
		};
		emc-timings-2 {
			nvidia,ram-code = <2>;
			timing-51000000 {
				clock-frequency = <51000000>;
				nvidia,emc-auto-cal-interval = <0x001fffff>;
				nvidia,emc-mode-1 = <0x80100003>;
				nvidia,emc-mode-2 = <0x80200008>;
				nvidia,emc-mode-reset = <0x80001221>;
				nvidia,emc-zcal-cnt-long = <0x00000040>;
				nvidia,emc-cfg-periodic-qrst;
				nvidia,emc-cfg-dyn-self-ref;
				nvidia,emc-configuration = <
					0x00000002 /* EMC_RC */
					0x0000000f /* EMC_RFC */
					0x00000001 /* EMC_RAS */
					0x00000000 /* EMC_RP */
					0x00000002 /* EMC_R2W */
					0x0000000a /* EMC_W2R */
					0x00000003 /* EMC_R2P */
					0x0000000b /* EMC_W2P */
					0x00000000 /* EMC_RD_RCD */
					0x00000000 /* EMC_WR_RCD */
					0x00000003 /* EMC_RRD */
					0x00000001 /* EMC_REXT */
					0x00000000 /* EMC_WEXT */
					0x00000005 /* EMC_WDV */
					0x00000005 /* EMC_QUSE */
					0x00000004 /* EMC_QRST */
					0x00000009 /* EMC_QSAFE */
					0x0000000b /* EMC_RDV */
					0x00000181 /* EMC_REFRESH */
					0x00000000 /* EMC_BURST_REFRESH_NUM */
					0x00000060 /* EMC_PRE_REFRESH_REQ_CNT */
					0x00000002 /* EMC_PDEX2WR */
					0x00000002 /* EMC_PDEX2RD */
					0x00000001 /* EMC_PCHG2PDEN */
					0x00000000 /* EMC_ACT2PDEN */
					0x00000007 /* EMC_AR2PDEN */
					0x0000000f /* EMC_RW2PDEN */
					0x00000010 /* EMC_TXSR */
					0x00000010 /* EMC_TXSRDLL */
					0x00000004 /* EMC_TCKE */
					0x00000002 /* EMC_TFAW */
					0x00000000 /* EMC_TRPAB */
					0x00000004 /* EMC_TCLKSTABLE */
					0x00000005 /* EMC_TCLKSTOP */
					0x0000018e /* EMC_TREFBW */
					0x00000006 /* EMC_QUSE_EXTRA */
					0x00000004 /* EMC_FBIO_CFG6 */
					0x00000000 /* EMC_ODT_WRITE */
					0x00000000 /* EMC_ODT_READ */
					0x00004288 /* EMC_FBIO_CFG5 */
					0x007800a4 /* EMC_CFG_DIG_DLL */
					0x00008000 /* EMC_CFG_DIG_DLL_PERIOD */
					0x000fc000 /* EMC_DLL_XFORM_DQS0 */
					0x000fc000 /* EMC_DLL_XFORM_DQS1 */
					0x000fc000 /* EMC_DLL_XFORM_DQS2 */
					0x000fc000 /* EMC_DLL_XFORM_DQS3 */
					0x000fc000 /* EMC_DLL_XFORM_DQS4 */
					0x000fc000 /* EMC_DLL_XFORM_DQS5 */
					0x000fc000 /* EMC_DLL_XFORM_DQS6 */
					0x000fc000 /* EMC_DLL_XFORM_DQS7 */
					0x00000000 /* EMC_DLL_XFORM_QUSE0 */
					0x00000000 /* EMC_DLL_XFORM_QUSE1 */
					0x00000000 /* EMC_DLL_XFORM_QUSE2 */
					0x00000000 /* EMC_DLL_XFORM_QUSE3 */
					0x00000000 /* EMC_DLL_XFORM_QUSE4 */
					0x00000000 /* EMC_DLL_XFORM_QUSE5 */
					0x00000000 /* EMC_DLL_XFORM_QUSE6 */
					0x00000000 /* EMC_DLL_XFORM_QUSE7 */
					0x00000000 /* EMC_DLI_TRIM_TXDQS0 */
					0x00000000 /* EMC_DLI_TRIM_TXDQS1 */
					0x00000000 /* EMC_DLI_TRIM_TXDQS2 */
					0x00000000 /* EMC_DLI_TRIM_TXDQS3 */
					0x00000000 /* EMC_DLI_TRIM_TXDQS4 */
					0x00000000 /* EMC_DLI_TRIM_TXDQS5 */
					0x00000000 /* EMC_DLI_TRIM_TXDQS6 */
					0x00000000 /* EMC_DLI_TRIM_TXDQS7 */
					0x000fc000 /* EMC_DLL_XFORM_DQ0 */
					0x000fc000 /* EMC_DLL_XFORM_DQ1 */
					0x000fc000 /* EMC_DLL_XFORM_DQ2 */
					0x000fc000 /* EMC_DLL_XFORM_DQ3 */
					0x000002a0 /* EMC_XM2CMDPADCTRL */
					0x0800211c /* EMC_XM2DQSPADCTRL2 */
					0x00000000 /* EMC_XM2DQPADCTRL2 */
					0x77fff884 /* EMC_XM2CLKPADCTRL */
					0x01f1f108 /* EMC_XM2COMPPADCTRL */
					0x05057404 /* EMC_XM2VTTGENPADCTRL */
					0x54000007 /* EMC_XM2VTTGENPADCTRL2 */
					0x08000168 /* EMC_XM2QUSEPADCTRL */
					0x08000000 /* EMC_XM2DQSPADCTRL3 */
					0x00000802 /* EMC_CTT_TERM_CTRL */
					0x00000000 /* EMC_ZCAL_INTERVAL */
					0x00000040 /* EMC_ZCAL_WAIT_CNT */
					0x000c000c /* EMC_MRS_WAIT_CNT */
					0xa0f10000 /* EMC_AUTO_CAL_CONFIG */
					0x00000000 /* EMC_CTT */
					0x00000000 /* EMC_CTT_DURATION */
					0x8000040b /* EMC_DYN_SELF_REF_CONTROL */
					0xe8000000 /* EMC_FBIO_SPARE */
					0xff00ff00 /* EMC_CFG_RSV */
				>;
			};
			timing-102000000 {
				clock-frequency = <102000000>;
				nvidia,emc-auto-cal-interval = <0x001fffff>;
				nvidia,emc-mode-1 = <0x80100003>;
				nvidia,emc-mode-2 = <0x80200008>;
				nvidia,emc-mode-reset = <0x80001221>;
				nvidia,emc-zcal-cnt-long = <0x00000040>;
				nvidia,emc-cfg-periodic-qrst;
				nvidia,emc-cfg-dyn-self-ref;
				nvidia,emc-configuration = <
					0x00000004 /* EMC_RC */
					0x0000001e /* EMC_RFC */
					0x00000003 /* EMC_RAS */
					0x00000001 /* EMC_RP */
					0x00000002 /* EMC_R2W */
					0x0000000a /* EMC_W2R */
					0x00000003 /* EMC_R2P */
					0x0000000b /* EMC_W2P */
					0x00000001 /* EMC_RD_RCD */
					0x00000001 /* EMC_WR_RCD */
					0x00000003 /* EMC_RRD */
					0x00000001 /* EMC_REXT */
					0x00000000 /* EMC_WEXT */
					0x00000005 /* EMC_WDV */
					0x00000005 /* EMC_QUSE */
					0x00000004 /* EMC_QRST */
					0x00000009 /* EMC_QSAFE */
					0x0000000b /* EMC_RDV */
					0x00000303 /* EMC_REFRESH */
					0x00000000 /* EMC_BURST_REFRESH_NUM */
					0x000000c0 /* EMC_PRE_REFRESH_REQ_CNT */
					0x00000002 /* EMC_PDEX2WR */
					0x00000002 /* EMC_PDEX2RD */
					0x00000001 /* EMC_PCHG2PDEN */
					0x00000000 /* EMC_ACT2PDEN */
					0x00000007 /* EMC_AR2PDEN */
					0x0000000f /* EMC_RW2PDEN */
					0x00000020 /* EMC_TXSR */
					0x00000020 /* EMC_TXSRDLL */
					0x00000004 /* EMC_TCKE */
					0x00000004 /* EMC_TFAW */
					0x00000000 /* EMC_TRPAB */
					0x00000004 /* EMC_TCLKSTABLE */
					0x00000005 /* EMC_TCLKSTOP */
					0x0000031c /* EMC_TREFBW */
					0x00000006 /* EMC_QUSE_EXTRA */
					0x00000004 /* EMC_FBIO_CFG6 */
					0x00000000 /* EMC_ODT_WRITE */
					0x00000000 /* EMC_ODT_READ */
					0x00004288 /* EMC_FBIO_CFG5 */
					0x007800a4 /* EMC_CFG_DIG_DLL */
					0x00008000 /* EMC_CFG_DIG_DLL_PERIOD */
					0x000fc000 /* EMC_DLL_XFORM_DQS0 */
					0x000fc000 /* EMC_DLL_XFORM_DQS1 */
					0x000fc000 /* EMC_DLL_XFORM_DQS2 */
					0x000fc000 /* EMC_DLL_XFORM_DQS3 */
					0x000fc000 /* EMC_DLL_XFORM_DQS4 */
					0x000fc000 /* EMC_DLL_XFORM_DQS5 */
					0x000fc000 /* EMC_DLL_XFORM_DQS6 */
					0x000fc000 /* EMC_DLL_XFORM_DQS7 */
					0x00000000 /* EMC_DLL_XFORM_QUSE0 */
					0x00000000 /* EMC_DLL_XFORM_QUSE1 */
					0x00000000 /* EMC_DLL_XFORM_QUSE2 */
					0x00000000 /* EMC_DLL_XFORM_QUSE3 */
					0x00000000 /* EMC_DLL_XFORM_QUSE4 */
					0x00000000 /* EMC_DLL_XFORM_QUSE5 */
					0x00000000 /* EMC_DLL_XFORM_QUSE6 */
					0x00000000 /* EMC_DLL_XFORM_QUSE7 */
					0x00000000 /* EMC_DLI_TRIM_TXDQS0 */
					0x00000000 /* EMC_DLI_TRIM_TXDQS1 */
					0x00000000 /* EMC_DLI_TRIM_TXDQS2 */
					0x00000000 /* EMC_DLI_TRIM_TXDQS3 */
					0x00000000 /* EMC_DLI_TRIM_TXDQS4 */
					0x00000000 /* EMC_DLI_TRIM_TXDQS5 */
					0x00000000 /* EMC_DLI_TRIM_TXDQS6 */
					0x00000000 /* EMC_DLI_TRIM_TXDQS7 */
					0x000fc000 /* EMC_DLL_XFORM_DQ0 */
					0x000fc000 /* EMC_DLL_XFORM_DQ1 */
					0x000fc000 /* EMC_DLL_XFORM_DQ2 */
					0x000fc000 /* EMC_DLL_XFORM_DQ3 */
					0x000002a0 /* EMC_XM2CMDPADCTRL */
					0x0800211c /* EMC_XM2DQSPADCTRL2 */
					0x00000000 /* EMC_XM2DQPADCTRL2 */
					0x77fff884 /* EMC_XM2CLKPADCTRL */
					0x01f1f108 /* EMC_XM2COMPPADCTRL */
					0x05057404 /* EMC_XM2VTTGENPADCTRL */
					0x54000007 /* EMC_XM2VTTGENPADCTRL2 */
					0x08000168 /* EMC_XM2QUSEPADCTRL */
					0x08000000 /* EMC_XM2DQSPADCTRL3 */
					0x00000802 /* EMC_CTT_TERM_CTRL */
					0x00000000 /* EMC_ZCAL_INTERVAL */
					0x00000040 /* EMC_ZCAL_WAIT_CNT */
					0x000c000c /* EMC_MRS_WAIT_CNT */
					0xa0f10000 /* EMC_AUTO_CAL_CONFIG */
					0x00000000 /* EMC_CTT */
					0x00000000 /* EMC_CTT_DURATION */
					0x80000713 /* EMC_DYN_SELF_REF_CONTROL */
					0xe8000000 /* EMC_FBIO_SPARE */
					0xff00ff00 /* EMC_CFG_RSV */
				>;
			};
			timing-375000000 {
				clock-frequency = <375000000>;
				nvidia,emc-auto-cal-interval = <0x001fffff>;
				nvidia,emc-mode-1 = <0x80100002>;
				nvidia,emc-mode-2 = <0x80200000>;
				nvidia,emc-mode-reset = <0x80000521>;
				nvidia,emc-zcal-cnt-long = <0x00000040>;
				nvidia,emc-configuration = <
					0x00000011 /* EMC_RC */
					0x0000006f /* EMC_RFC */
					0x0000000c /* EMC_RAS */
					0x00000004 /* EMC_RP */
					0x00000003 /* EMC_R2W */
					0x00000008 /* EMC_W2R */
					0x00000002 /* EMC_R2P */
					0x0000000a /* EMC_W2P */
					0x00000004 /* EMC_RD_RCD */
					0x00000004 /* EMC_WR_RCD */
					0x00000002 /* EMC_RRD */
					0x00000001 /* EMC_REXT */
					0x00000000 /* EMC_WEXT */
					0x00000004 /* EMC_WDV */
					0x00000006 /* EMC_QUSE */
					0x00000004 /* EMC_QRST */
					0x0000000a /* EMC_QSAFE */
					0x0000000c /* EMC_RDV */
					0x00000b2d /* EMC_REFRESH */
					0x00000000 /* EMC_BURST_REFRESH_NUM */
					0x000002cb /* EMC_PRE_REFRESH_REQ_CNT */
					0x00000001 /* EMC_PDEX2WR */
					0x00000008 /* EMC_PDEX2RD */
					0x00000001 /* EMC_PCHG2PDEN */
					0x00000000 /* EMC_ACT2PDEN */
					0x00000007 /* EMC_AR2PDEN */
					0x0000000f /* EMC_RW2PDEN */
					0x00000075 /* EMC_TXSR */
					0x00000200 /* EMC_TXSRDLL */
					0x00000004 /* EMC_TCKE */
					0x0000000c /* EMC_TFAW */
					0x00000000 /* EMC_TRPAB */
					0x00000004 /* EMC_TCLKSTABLE */
					0x00000005 /* EMC_TCLKSTOP */
					0x00000b6d /* EMC_TREFBW */
					0x00000000 /* EMC_QUSE_EXTRA */
					0x00000004 /* EMC_FBIO_CFG6 */
					0x00000000 /* EMC_ODT_WRITE */
					0x00000000 /* EMC_ODT_READ */
					0x00007088 /* EMC_FBIO_CFG5 */
					0x00200084 /* EMC_CFG_DIG_DLL */
					0x00008000 /* EMC_CFG_DIG_DLL_PERIOD */
					0x00028000 /* EMC_DLL_XFORM_DQS0 */
					0x00028000 /* EMC_DLL_XFORM_DQS1 */
					0x00028000 /* EMC_DLL_XFORM_DQS2 */
					0x00028000 /* EMC_DLL_XFORM_DQS3 */
					0x00028000 /* EMC_DLL_XFORM_DQS4 */
					0x00028000 /* EMC_DLL_XFORM_DQS5 */
					0x00028000 /* EMC_DLL_XFORM_DQS6 */
					0x00028000 /* EMC_DLL_XFORM_DQS7 */
					0x00000000 /* EMC_DLL_XFORM_QUSE0 */
					0x00000000 /* EMC_DLL_XFORM_QUSE1 */
					0x00000000 /* EMC_DLL_XFORM_QUSE2 */
					0x00000000 /* EMC_DLL_XFORM_QUSE3 */
					0x00000000 /* EMC_DLL_XFORM_QUSE4 */
					0x00000000 /* EMC_DLL_XFORM_QUSE5 */
					0x00000000 /* EMC_DLL_XFORM_QUSE6 */
					0x00000000 /* EMC_DLL_XFORM_QUSE7 */
					0x00000000 /* EMC_DLI_TRIM_TXDQS0 */
					0x00000000 /* EMC_DLI_TRIM_TXDQS1 */
					0x00000000 /* EMC_DLI_TRIM_TXDQS2 */
					0x00000000 /* EMC_DLI_TRIM_TXDQS3 */
					0x00000000 /* EMC_DLI_TRIM_TXDQS4 */
					0x00000000 /* EMC_DLI_TRIM_TXDQS5 */
					0x00000000 /* EMC_DLI_TRIM_TXDQS6 */
					0x00000000 /* EMC_DLI_TRIM_TXDQS7 */
					0x00044000 /* EMC_DLL_XFORM_DQ0 */
					0x00044000 /* EMC_DLL_XFORM_DQ1 */
					0x00044000 /* EMC_DLL_XFORM_DQ2 */
					0x00044000 /* EMC_DLL_XFORM_DQ3 */
					0x000002a0 /* EMC_XM2CMDPADCTRL */
					0x0800013d /* EMC_XM2DQSPADCTRL2 */
					0x00000000 /* EMC_XM2DQPADCTRL2 */
					0x77fff884 /* EMC_XM2CLKPADCTRL */
					0x01f1f508 /* EMC_XM2COMPPADCTRL */
					0x05057404 /* EMC_XM2VTTGENPADCTRL */
					0x54000007 /* EMC_XM2VTTGENPADCTRL2 */
					0x080001e8 /* EMC_XM2QUSEPADCTRL */
					0x08000021 /* EMC_XM2DQSPADCTRL3 */
					0x00000802 /* EMC_CTT_TERM_CTRL */
					0x00020000 /* EMC_ZCAL_INTERVAL */
					0x00000100 /* EMC_ZCAL_WAIT_CNT */
					0x0150000c /* EMC_MRS_WAIT_CNT */
					0xa0f10000 /* EMC_AUTO_CAL_CONFIG */
					0x00000000 /* EMC_CTT */
					0x00000000 /* EMC_CTT_DURATION */
					0x8000174b /* EMC_DYN_SELF_REF_CONTROL */
					0xe8000000 /* EMC_FBIO_SPARE */
					0xff00ff89 /* EMC_CFG_RSV */
				>;
			};
			timing-750000000 {
				clock-frequency = <750000000>;
				nvidia,emc-auto-cal-interval = <0x001fffff>;
				nvidia,emc-mode-1 = <0x80100002>;
				nvidia,emc-mode-2 = <0x80200018>;
				nvidia,emc-mode-reset = <0x80001d71>;
				nvidia,emc-zcal-cnt-long = <0x00000040>;
				nvidia,emc-cfg-periodic-qrst;
				nvidia,emc-configuration = <
					0x00000023 /* EMC_RC */
					0x000000df /* EMC_RFC */
					0x00000019 /* EMC_RAS */
					0x00000009 /* EMC_RP */
					0x00000005 /* EMC_R2W */
					0x0000000d /* EMC_W2R */
					0x00000004 /* EMC_R2P */
					0x00000013 /* EMC_W2P */
					0x00000009 /* EMC_RD_RCD */
					0x00000009 /* EMC_WR_RCD */
					0x00000006 /* EMC_RRD */
					0x00000001 /* EMC_REXT */
					0x00000000 /* EMC_WEXT */
					0x00000007 /* EMC_WDV */
					0x0000000c /* EMC_QUSE */
					0x00000009 /* EMC_QRST */
					0x0000000d /* EMC_QSAFE */
					0x00000012 /* EMC_RDV */
					0x0000169a /* EMC_REFRESH */
					0x00000000 /* EMC_BURST_REFRESH_NUM */
					0x000005a6 /* EMC_PRE_REFRESH_REQ_CNT */
					0x00000003 /* EMC_PDEX2WR */
					0x00000003 /* EMC_PDEX2RD */
					0x00000001 /* EMC_PCHG2PDEN */
					0x00000000 /* EMC_ACT2PDEN */
					0x0000000e /* EMC_AR2PDEN */
					0x00000018 /* EMC_RW2PDEN */
					0x000000e9 /* EMC_TXSR */
					0x00000200 /* EMC_TXSRDLL */
					0x00000005 /* EMC_TCKE */
					0x00000017 /* EMC_TFAW */
					0x00000000 /* EMC_TRPAB */
					0x00000007 /* EMC_TCLKSTABLE */
					0x00000008 /* EMC_TCLKSTOP */
					0x000016da /* EMC_TREFBW */
					0x00000000 /* EMC_QUSE_EXTRA */
					0x00000004 /* EMC_FBIO_CFG6 */
					0x00000000 /* EMC_ODT_WRITE */
					0x00000000 /* EMC_ODT_READ */
					0x00005088 /* EMC_FBIO_CFG5 */
					0x70070191 /* EMC_CFG_DIG_DLL */
					0x00008000 /* EMC_CFG_DIG_DLL_PERIOD */
					0x00000006 /* EMC_DLL_XFORM_DQS0 */
					0x00000006 /* EMC_DLL_XFORM_DQS1 */
					0x00000006 /* EMC_DLL_XFORM_DQS2 */
					0x00000006 /* EMC_DLL_XFORM_DQS3 */
					0x00000010 /* EMC_DLL_XFORM_DQS4 */
					0x00000010 /* EMC_DLL_XFORM_DQS5 */
					0x00000010 /* EMC_DLL_XFORM_DQS6 */
					0x00000010 /* EMC_DLL_XFORM_DQS7 */
					0x00000000 /* EMC_DLL_XFORM_QUSE0 */
					0x00000000 /* EMC_DLL_XFORM_QUSE1 */
					0x00000000 /* EMC_DLL_XFORM_QUSE2 */
					0x00000000 /* EMC_DLL_XFORM_QUSE3 */
					0x00000008 /* EMC_DLL_XFORM_QUSE4 */
					0x00000008 /* EMC_DLL_XFORM_QUSE5 */
					0x00000008 /* EMC_DLL_XFORM_QUSE6 */
					0x00000008 /* EMC_DLL_XFORM_QUSE7 */
					0x00000000 /* EMC_DLI_TRIM_TXDQS0 */
					0x00000000 /* EMC_DLI_TRIM_TXDQS1 */
					0x00000000 /* EMC_DLI_TRIM_TXDQS2 */
					0x00000000 /* EMC_DLI_TRIM_TXDQS3 */
					0x00000000 /* EMC_DLI_TRIM_TXDQS4 */
					0x00000000 /* EMC_DLI_TRIM_TXDQS5 */
					0x00000000 /* EMC_DLI_TRIM_TXDQS6 */
					0x00000000 /* EMC_DLI_TRIM_TXDQS7 */
					0x0000000e /* EMC_DLL_XFORM_DQ0 */
					0x0000000e /* EMC_DLL_XFORM_DQ1 */
					0x0000000e /* EMC_DLL_XFORM_DQ2 */
					0x0000000e /* EMC_DLL_XFORM_DQ3 */
					0x000002a0 /* EMC_XM2CMDPADCTRL */
					0x0800013d /* EMC_XM2DQSPADCTRL2 */
					0x00000000 /* EMC_XM2DQPADCTRL2 */
					0x77fff884 /* EMC_XM2CLKPADCTRL */
					0x01f1f501 /* EMC_XM2COMPPADCTRL */
					0x07077404 /* EMC_XM2VTTGENPADCTRL */
					0x54000000 /* EMC_XM2VTTGENPADCTRL2 */
					0x080001e8 /* EMC_XM2QUSEPADCTRL */
					0x06000021 /* EMC_XM2DQSPADCTRL3 */
					0x00000802 /* EMC_CTT_TERM_CTRL */
					0x00000000 /* EMC_ZCAL_INTERVAL */
					0x00000040 /* EMC_ZCAL_WAIT_CNT */
					0x011f000c /* EMC_MRS_WAIT_CNT */
					0xa0f10606 /* EMC_AUTO_CAL_CONFIG */
					0x00000000 /* EMC_CTT */
					0x00000000 /* EMC_CTT_DURATION */
					0x80002d93 /* EMC_DYN_SELF_REF_CONTROL */
					0xe8000000 /* EMC_FBIO_SPARE */
					0xff00ff49 /* EMC_CFG_RSV */
				>;
			};
		};
		emc-timings-3 {
			nvidia,ram-code = <3>;
			timing-51000000 {
				clock-frequency = <51000000>;
				nvidia,emc-auto-cal-interval = <0x001fffff>;
				nvidia,emc-mode-1 = <0x80100003>;
				nvidia,emc-mode-2 = <0x80200008>;
				nvidia,emc-mode-reset = <0x80001221>;
				nvidia,emc-zcal-cnt-long = <0x00000040>;
				nvidia,emc-cfg-periodic-qrst;
				nvidia,emc-cfg-dyn-self-ref;
				nvidia,emc-configuration = <
					0x00000002 /* EMC_RC */
					0x0000000f /* EMC_RFC */
					0x00000001 /* EMC_RAS */
					0x00000000 /* EMC_RP */
					0x00000002 /* EMC_R2W */
					0x0000000a /* EMC_W2R */
					0x00000005 /* EMC_R2P */
					0x0000000b /* EMC_W2P */
					0x00000000 /* EMC_RD_RCD */
					0x00000000 /* EMC_WR_RCD */
					0x00000003 /* EMC_RRD */
					0x00000001 /* EMC_REXT */
					0x00000000 /* EMC_WEXT */
					0x00000005 /* EMC_WDV */
					0x00000005 /* EMC_QUSE */
					0x00000004 /* EMC_QRST */
					0x0000000a /* EMC_QSAFE */
					0x0000000b /* EMC_RDV */
					0x00000181 /* EMC_REFRESH */
					0x00000000 /* EMC_BURST_REFRESH_NUM */
					0x00000060 /* EMC_PRE_REFRESH_REQ_CNT */
					0x00000002 /* EMC_PDEX2WR */
					0x00000002 /* EMC_PDEX2RD */
					0x00000001 /* EMC_PCHG2PDEN */
					0x00000000 /* EMC_ACT2PDEN */
					0x00000007 /* EMC_AR2PDEN */
					0x0000000f /* EMC_RW2PDEN */
					0x00000010 /* EMC_TXSR */
					0x00000010 /* EMC_TXSRDLL */
					0x00000004 /* EMC_TCKE */
					0x00000002 /* EMC_TFAW */
					0x00000000 /* EMC_TRPAB */
					0x00000004 /* EMC_TCLKSTABLE */
					0x00000005 /* EMC_TCLKSTOP */
					0x0000018e /* EMC_TREFBW */
					0x00000006 /* EMC_QUSE_EXTRA */
					0x00000004 /* EMC_FBIO_CFG6 */
					0x00000000 /* EMC_ODT_WRITE */
					0x00000000 /* EMC_ODT_READ */
					0x00004288 /* EMC_FBIO_CFG5 */
					0x007800a4 /* EMC_CFG_DIG_DLL */
					0x00008000 /* EMC_CFG_DIG_DLL_PERIOD */
					0x000fc000 /* EMC_DLL_XFORM_DQS0 */
					0x000fc000 /* EMC_DLL_XFORM_DQS1 */
					0x000fc000 /* EMC_DLL_XFORM_DQS2 */
					0x000fc000 /* EMC_DLL_XFORM_DQS3 */
					0x000fc000 /* EMC_DLL_XFORM_DQS4 */
					0x000fc000 /* EMC_DLL_XFORM_DQS5 */
					0x000fc000 /* EMC_DLL_XFORM_DQS6 */
					0x000fc000 /* EMC_DLL_XFORM_DQS7 */
					0x00000000 /* EMC_DLL_XFORM_QUSE0 */
					0x00000000 /* EMC_DLL_XFORM_QUSE1 */
					0x00000000 /* EMC_DLL_XFORM_QUSE2 */
					0x00000000 /* EMC_DLL_XFORM_QUSE3 */
					0x00000000 /* EMC_DLL_XFORM_QUSE4 */
					0x00000000 /* EMC_DLL_XFORM_QUSE5 */
					0x00000000 /* EMC_DLL_XFORM_QUSE6 */
					0x00000000 /* EMC_DLL_XFORM_QUSE7 */
					0x00000000 /* EMC_DLI_TRIM_TXDQS0 */
					0x00000000 /* EMC_DLI_TRIM_TXDQS1 */
					0x00000000 /* EMC_DLI_TRIM_TXDQS2 */
					0x00000000 /* EMC_DLI_TRIM_TXDQS3 */
					0x00000000 /* EMC_DLI_TRIM_TXDQS4 */
					0x00000000 /* EMC_DLI_TRIM_TXDQS5 */
					0x00000000 /* EMC_DLI_TRIM_TXDQS6 */
					0x00000000 /* EMC_DLI_TRIM_TXDQS7 */
					0x000fc000 /* EMC_DLL_XFORM_DQ0 */
					0x000fc000 /* EMC_DLL_XFORM_DQ1 */
					0x000fc000 /* EMC_DLL_XFORM_DQ2 */
					0x000fc000 /* EMC_DLL_XFORM_DQ3 */
					0x000002a0 /* EMC_XM2CMDPADCTRL */
					0x0800211c /* EMC_XM2DQSPADCTRL2 */
					0x00000000 /* EMC_XM2DQPADCTRL2 */
					0x77fff884 /* EMC_XM2CLKPADCTRL */
					0x01f1f108 /* EMC_XM2COMPPADCTRL */
					0x05057404 /* EMC_XM2VTTGENPADCTRL */
					0x54000007 /* EMC_XM2VTTGENPADCTRL2 */
					0x08000168 /* EMC_XM2QUSEPADCTRL */
					0x08000000 /* EMC_XM2DQSPADCTRL3 */
					0x00000802 /* EMC_CTT_TERM_CTRL */
					0x00000000 /* EMC_ZCAL_INTERVAL */
					0x00000040 /* EMC_ZCAL_WAIT_CNT */
					0x000c000c /* EMC_MRS_WAIT_CNT */
					0xa0f10000 /* EMC_AUTO_CAL_CONFIG */
					0x00000000 /* EMC_CTT */
					0x00000000 /* EMC_CTT_DURATION */
					0x8000040b /* EMC_DYN_SELF_REF_CONTROL */
					0xe8000000 /* EMC_FBIO_SPARE */
					0xff00ff00 /* EMC_CFG_RSV */
				>;
			};
			timing-102000000 {
				clock-frequency = <102000000>;
				nvidia,emc-auto-cal-interval = <0x001fffff>;
				nvidia,emc-mode-1 = <0x80100003>;
				nvidia,emc-mode-2 = <0x80200008>;
				nvidia,emc-mode-reset = <0x80001221>;
				nvidia,emc-zcal-cnt-long = <0x00000040>;
				nvidia,emc-cfg-periodic-qrst;
				nvidia,emc-cfg-dyn-self-ref;
				nvidia,emc-configuration = <
					0x00000004 /* EMC_RC */
					0x0000001e /* EMC_RFC */
					0x00000003 /* EMC_RAS */
					0x00000001 /* EMC_RP */
					0x00000002 /* EMC_R2W */
					0x0000000a /* EMC_W2R */
					0x00000005 /* EMC_R2P */
					0x0000000b /* EMC_W2P */
					0x00000001 /* EMC_RD_RCD */
					0x00000001 /* EMC_WR_RCD */
					0x00000003 /* EMC_RRD */
					0x00000001 /* EMC_REXT */
					0x00000000 /* EMC_WEXT */
					0x00000005 /* EMC_WDV */
					0x00000005 /* EMC_QUSE */
					0x00000004 /* EMC_QRST */
					0x0000000a /* EMC_QSAFE */
					0x0000000b /* EMC_RDV */
					0x00000303 /* EMC_REFRESH */
					0x00000000 /* EMC_BURST_REFRESH_NUM */
					0x000000c0 /* EMC_PRE_REFRESH_REQ_CNT */
					0x00000002 /* EMC_PDEX2WR */
					0x00000002 /* EMC_PDEX2RD */
					0x00000001 /* EMC_PCHG2PDEN */
					0x00000000 /* EMC_ACT2PDEN */
					0x00000007 /* EMC_AR2PDEN */
					0x0000000f /* EMC_RW2PDEN */
					0x00000020 /* EMC_TXSR */
					0x00000020 /* EMC_TXSRDLL */
					0x00000004 /* EMC_TCKE */
					0x00000004 /* EMC_TFAW */
					0x00000000 /* EMC_TRPAB */
					0x00000004 /* EMC_TCLKSTABLE */
					0x00000005 /* EMC_TCLKSTOP */
					0x0000031c /* EMC_TREFBW */
					0x00000006 /* EMC_QUSE_EXTRA */
					0x00000004 /* EMC_FBIO_CFG6 */
					0x00000000 /* EMC_ODT_WRITE */
					0x00000000 /* EMC_ODT_READ */
					0x00004288 /* EMC_FBIO_CFG5 */
					0x007800a4 /* EMC_CFG_DIG_DLL */
					0x00008000 /* EMC_CFG_DIG_DLL_PERIOD */
					0x000fc000 /* EMC_DLL_XFORM_DQS0 */
					0x000fc000 /* EMC_DLL_XFORM_DQS1 */
					0x000fc000 /* EMC_DLL_XFORM_DQS2 */
					0x000fc000 /* EMC_DLL_XFORM_DQS3 */
					0x000fc000 /* EMC_DLL_XFORM_DQS4 */
					0x000fc000 /* EMC_DLL_XFORM_DQS5 */
					0x000fc000 /* EMC_DLL_XFORM_DQS6 */
					0x000fc000 /* EMC_DLL_XFORM_DQS7 */
					0x00000000 /* EMC_DLL_XFORM_QUSE0 */
					0x00000000 /* EMC_DLL_XFORM_QUSE1 */
					0x00000000 /* EMC_DLL_XFORM_QUSE2 */
					0x00000000 /* EMC_DLL_XFORM_QUSE3 */
					0x00000000 /* EMC_DLL_XFORM_QUSE4 */
					0x00000000 /* EMC_DLL_XFORM_QUSE5 */
					0x00000000 /* EMC_DLL_XFORM_QUSE6 */
					0x00000000 /* EMC_DLL_XFORM_QUSE7 */
					0x00000000 /* EMC_DLI_TRIM_TXDQS0 */
					0x00000000 /* EMC_DLI_TRIM_TXDQS1 */
					0x00000000 /* EMC_DLI_TRIM_TXDQS2 */
					0x00000000 /* EMC_DLI_TRIM_TXDQS3 */
					0x00000000 /* EMC_DLI_TRIM_TXDQS4 */
					0x00000000 /* EMC_DLI_TRIM_TXDQS5 */
					0x00000000 /* EMC_DLI_TRIM_TXDQS6 */
					0x00000000 /* EMC_DLI_TRIM_TXDQS7 */
					0x000fc000 /* EMC_DLL_XFORM_DQ0 */
					0x000fc000 /* EMC_DLL_XFORM_DQ1 */
					0x000fc000 /* EMC_DLL_XFORM_DQ2 */
					0x000fc000 /* EMC_DLL_XFORM_DQ3 */
					0x000002a0 /* EMC_XM2CMDPADCTRL */
					0x0800211c /* EMC_XM2DQSPADCTRL2 */
					0x00000000 /* EMC_XM2DQPADCTRL2 */
					0x77fff884 /* EMC_XM2CLKPADCTRL */
					0x01f1f108 /* EMC_XM2COMPPADCTRL */
					0x05057404 /* EMC_XM2VTTGENPADCTRL */
					0x54000007 /* EMC_XM2VTTGENPADCTRL2 */
					0x08000168 /* EMC_XM2QUSEPADCTRL */
					0x08000000 /* EMC_XM2DQSPADCTRL3 */
					0x00000802 /* EMC_CTT_TERM_CTRL */
					0x00000000 /* EMC_ZCAL_INTERVAL */
					0x00000040 /* EMC_ZCAL_WAIT_CNT */
					0x000c000c /* EMC_MRS_WAIT_CNT */
					0xa0f10000 /* EMC_AUTO_CAL_CONFIG */
					0x00000000 /* EMC_CTT */
					0x00000000 /* EMC_CTT_DURATION */
					0x80000713 /* EMC_DYN_SELF_REF_CONTROL */
					0xe8000000 /* EMC_FBIO_SPARE */
					0xff00ff00 /* EMC_CFG_RSV */
				>;
			};
			timing-204000000 {
				clock-frequency = <204000000>;
				nvidia,emc-auto-cal-interval = <0x001fffff>;
				nvidia,emc-mode-1 = <0x80100003>;
				nvidia,emc-mode-2 = <0x80200008>;
				nvidia,emc-mode-reset = <0x80001221>;
				nvidia,emc-zcal-cnt-long = <0x00000040>;
				nvidia,emc-cfg-periodic-qrst;
				nvidia,emc-cfg-dyn-self-ref;
				nvidia,emc-configuration = <
					0x00000009 /* EMC_RC */
					0x0000003d /* EMC_RFC */
					0x00000007 /* EMC_RAS */
					0x00000002 /* EMC_RP */
					0x00000002 /* EMC_R2W */
					0x0000000a /* EMC_W2R */
					0x00000005 /* EMC_R2P */
					0x0000000b /* EMC_W2P */
					0x00000002 /* EMC_RD_RCD */
					0x00000002 /* EMC_WR_RCD */
					0x00000003 /* EMC_RRD */
					0x00000001 /* EMC_REXT */
					0x00000000 /* EMC_WEXT */
					0x00000005 /* EMC_WDV */
					0x00000005 /* EMC_QUSE */
					0x00000004 /* EMC_QRST */
					0x0000000a /* EMC_QSAFE */
					0x0000000b /* EMC_RDV */
					0x00000607 /* EMC_REFRESH */
					0x00000000 /* EMC_BURST_REFRESH_NUM */
					0x00000181 /* EMC_PRE_REFRESH_REQ_CNT */
					0x00000002 /* EMC_PDEX2WR */
					0x00000002 /* EMC_PDEX2RD */
					0x00000001 /* EMC_PCHG2PDEN */
					0x00000000 /* EMC_ACT2PDEN */
					0x00000007 /* EMC_AR2PDEN */
					0x0000000f /* EMC_RW2PDEN */
					0x00000040 /* EMC_TXSR */
					0x00000040 /* EMC_TXSRDLL */
					0x00000004 /* EMC_TCKE */
					0x00000007 /* EMC_TFAW */
					0x00000000 /* EMC_TRPAB */
					0x00000004 /* EMC_TCLKSTABLE */
					0x00000005 /* EMC_TCLKSTOP */
					0x00000638 /* EMC_TREFBW */
					0x00000006 /* EMC_QUSE_EXTRA */
					0x00000004 /* EMC_FBIO_CFG6 */
					0x00000000 /* EMC_ODT_WRITE */
					0x00000000 /* EMC_ODT_READ */
					0x00004288 /* EMC_FBIO_CFG5 */
					0x004400a4 /* EMC_CFG_DIG_DLL */
					0x00008000 /* EMC_CFG_DIG_DLL_PERIOD */
					0x00080000 /* EMC_DLL_XFORM_DQS0 */
					0x00080000 /* EMC_DLL_XFORM_DQS1 */
					0x00080000 /* EMC_DLL_XFORM_DQS2 */
					0x00080000 /* EMC_DLL_XFORM_DQS3 */
					0x00080000 /* EMC_DLL_XFORM_DQS4 */
					0x00080000 /* EMC_DLL_XFORM_DQS5 */
					0x00080000 /* EMC_DLL_XFORM_DQS6 */
					0x00080000 /* EMC_DLL_XFORM_DQS7 */
					0x00000000 /* EMC_DLL_XFORM_QUSE0 */
					0x00000000 /* EMC_DLL_XFORM_QUSE1 */
					0x00000000 /* EMC_DLL_XFORM_QUSE2 */
					0x00000000 /* EMC_DLL_XFORM_QUSE3 */
					0x00000000 /* EMC_DLL_XFORM_QUSE4 */
					0x00000000 /* EMC_DLL_XFORM_QUSE5 */
					0x00000000 /* EMC_DLL_XFORM_QUSE6 */
					0x00000000 /* EMC_DLL_XFORM_QUSE7 */
					0x00000000 /* EMC_DLI_TRIM_TXDQS0 */
					0x00000000 /* EMC_DLI_TRIM_TXDQS1 */
					0x00000000 /* EMC_DLI_TRIM_TXDQS2 */
					0x00000000 /* EMC_DLI_TRIM_TXDQS3 */
					0x00000000 /* EMC_DLI_TRIM_TXDQS4 */
					0x00000000 /* EMC_DLI_TRIM_TXDQS5 */
					0x00000000 /* EMC_DLI_TRIM_TXDQS6 */
					0x00000000 /* EMC_DLI_TRIM_TXDQS7 */
					0x00080000 /* EMC_DLL_XFORM_DQ0 */
					0x00080000 /* EMC_DLL_XFORM_DQ1 */
					0x00080000 /* EMC_DLL_XFORM_DQ2 */
					0x00080000 /* EMC_DLL_XFORM_DQ3 */
					0x000002a0 /* EMC_XM2CMDPADCTRL */
					0x0800211c /* EMC_XM2DQSPADCTRL2 */
					0x00000000 /* EMC_XM2DQPADCTRL2 */
					0x77fff884 /* EMC_XM2CLKPADCTRL */
					0x01f1f108 /* EMC_XM2COMPPADCTRL */
					0x05057404 /* EMC_XM2VTTGENPADCTRL */
					0x54000007 /* EMC_XM2VTTGENPADCTRL2 */
					0x08000168 /* EMC_XM2QUSEPADCTRL */
					0x08000000 /* EMC_XM2DQSPADCTRL3 */
					0x00000802 /* EMC_CTT_TERM_CTRL */
					0x00020000 /* EMC_ZCAL_INTERVAL */
					0x00000100 /* EMC_ZCAL_WAIT_CNT */
					0x000c000c /* EMC_MRS_WAIT_CNT */
					0xa0f10000 /* EMC_AUTO_CAL_CONFIG */
					0x00000000 /* EMC_CTT */
					0x00000000 /* EMC_CTT_DURATION */
					0x80000d22 /* EMC_DYN_SELF_REF_CONTROL */
					0xe8000000 /* EMC_FBIO_SPARE */
					0xff00ff00 /* EMC_CFG_RSV */
				>;
			};
			timing-375000000 {
				clock-frequency = <375000000>;
				nvidia,emc-auto-cal-interval = <0x001fffff>;
				nvidia,emc-mode-1 = <0x80100002>;
				nvidia,emc-mode-2 = <0x80200000>;
				nvidia,emc-mode-reset = <0x80000521>;
				nvidia,emc-zcal-cnt-long = <0x00000040>;
				nvidia,emc-configuration = <
					0x00000011 /* EMC_RC */
					0x0000006f /* EMC_RFC */
					0x0000000c /* EMC_RAS */
					0x00000004 /* EMC_RP */
					0x00000003 /* EMC_R2W */
					0x00000008 /* EMC_W2R */
					0x00000002 /* EMC_R2P */
					0x0000000a /* EMC_W2P */
					0x00000004 /* EMC_RD_RCD */
					0x00000004 /* EMC_WR_RCD */
					0x00000002 /* EMC_RRD */
					0x00000001 /* EMC_REXT */
					0x00000000 /* EMC_WEXT */
					0x00000004 /* EMC_WDV */
					0x00000006 /* EMC_QUSE */
					0x00000004 /* EMC_QRST */
					0x0000000a /* EMC_QSAFE */
					0x0000000c /* EMC_RDV */
					0x00000b2d /* EMC_REFRESH */
					0x00000000 /* EMC_BURST_REFRESH_NUM */
					0x000002cb /* EMC_PRE_REFRESH_REQ_CNT */
					0x00000001 /* EMC_PDEX2WR */
					0x00000008 /* EMC_PDEX2RD */
					0x00000001 /* EMC_PCHG2PDEN */
					0x00000000 /* EMC_ACT2PDEN */
					0x00000007 /* EMC_AR2PDEN */
					0x0000000f /* EMC_RW2PDEN */
					0x00000075 /* EMC_TXSR */
					0x00000200 /* EMC_TXSRDLL */
					0x00000004 /* EMC_TCKE */
					0x0000000c /* EMC_TFAW */
					0x00000000 /* EMC_TRPAB */
					0x00000004 /* EMC_TCLKSTABLE */
					0x00000005 /* EMC_TCLKSTOP */
					0x00000b6d /* EMC_TREFBW */
					0x00000000 /* EMC_QUSE_EXTRA */
					0x00000004 /* EMC_FBIO_CFG6 */
					0x00000000 /* EMC_ODT_WRITE */
					0x00000000 /* EMC_ODT_READ */
					0x00007088 /* EMC_FBIO_CFG5 */
					0x00200084 /* EMC_CFG_DIG_DLL */
					0x00008000 /* EMC_CFG_DIG_DLL_PERIOD */
					0x00040000 /* EMC_DLL_XFORM_DQS0 */
					0x00040000 /* EMC_DLL_XFORM_DQS1 */
					0x00040000 /* EMC_DLL_XFORM_DQS2 */
					0x00040000 /* EMC_DLL_XFORM_DQS3 */
					0x00040000 /* EMC_DLL_XFORM_DQS4 */
					0x00040000 /* EMC_DLL_XFORM_DQS5 */
					0x00040000 /* EMC_DLL_XFORM_DQS6 */
					0x00040000 /* EMC_DLL_XFORM_DQS7 */
					0x00000000 /* EMC_DLL_XFORM_QUSE0 */
					0x00000000 /* EMC_DLL_XFORM_QUSE1 */
					0x00000000 /* EMC_DLL_XFORM_QUSE2 */
					0x00000000 /* EMC_DLL_XFORM_QUSE3 */
					0x00000000 /* EMC_DLL_XFORM_QUSE4 */
					0x00000000 /* EMC_DLL_XFORM_QUSE5 */
					0x00000000 /* EMC_DLL_XFORM_QUSE6 */
					0x00000000 /* EMC_DLL_XFORM_QUSE7 */
					0x00000000 /* EMC_DLI_TRIM_TXDQS0 */
					0x00000000 /* EMC_DLI_TRIM_TXDQS1 */
					0x00000000 /* EMC_DLI_TRIM_TXDQS2 */
					0x00000000 /* EMC_DLI_TRIM_TXDQS3 */
					0x00000000 /* EMC_DLI_TRIM_TXDQS4 */
					0x00000000 /* EMC_DLI_TRIM_TXDQS5 */
					0x00000000 /* EMC_DLI_TRIM_TXDQS6 */
					0x00000000 /* EMC_DLI_TRIM_TXDQS7 */
					0x00050000 /* EMC_DLL_XFORM_DQ0 */
					0x00050000 /* EMC_DLL_XFORM_DQ1 */
					0x00050000 /* EMC_DLL_XFORM_DQ2 */
					0x00050000 /* EMC_DLL_XFORM_DQ3 */
					0x000002a0 /* EMC_XM2CMDPADCTRL */
					0x0800013d /* EMC_XM2DQSPADCTRL2 */
					0x00000000 /* EMC_XM2DQPADCTRL2 */
					0x77fff884 /* EMC_XM2CLKPADCTRL */
					0x01f1f508 /* EMC_XM2COMPPADCTRL */
					0x05057404 /* EMC_XM2VTTGENPADCTRL */
					0x54000007 /* EMC_XM2VTTGENPADCTRL2 */
					0x080001e8 /* EMC_XM2QUSEPADCTRL */
					0x08000021 /* EMC_XM2DQSPADCTRL3 */
					0x00000802 /* EMC_CTT_TERM_CTRL */
					0x00020000 /* EMC_ZCAL_INTERVAL */
					0x00000100 /* EMC_ZCAL_WAIT_CNT */
					0x0150000c /* EMC_MRS_WAIT_CNT */
					0xa0f10000 /* EMC_AUTO_CAL_CONFIG */
					0x00000000 /* EMC_CTT */
					0x00000000 /* EMC_CTT_DURATION */
					0x8000174b /* EMC_DYN_SELF_REF_CONTROL */
					0xe8000000 /* EMC_FBIO_SPARE */
					0xff00ff89 /* EMC_CFG_RSV */
				>;
			};
			timing-750000000 {
				clock-frequency = <750000000>;
				nvidia,emc-auto-cal-interval = <0x001fffff>;
				nvidia,emc-mode-1 = <0x80100002>;
				nvidia,emc-mode-2 = <0x80200018>;
				nvidia,emc-mode-reset = <0x80000d71>;
				nvidia,emc-zcal-cnt-long = <0x00000040>;
				nvidia,emc-cfg-periodic-qrst;
				nvidia,emc-configuration = <
					0x00000023 /* EMC_RC */
					0x000000df /* EMC_RFC */
					0x00000019 /* EMC_RAS */
					0x00000009 /* EMC_RP */
					0x00000005 /* EMC_R2W */
					0x0000000d /* EMC_W2R */
					0x00000004 /* EMC_R2P */
					0x00000013 /* EMC_W2P */
					0x00000009 /* EMC_RD_RCD */
					0x00000009 /* EMC_WR_RCD */
					0x00000006 /* EMC_RRD */
					0x00000001 /* EMC_REXT */
					0x00000000 /* EMC_WEXT */
					0x00000007 /* EMC_WDV */
					0x0000000b /* EMC_QUSE */
					0x00000009 /* EMC_QRST */
					0x0000000d /* EMC_QSAFE */
					0x00000011 /* EMC_RDV */
					0x0000169a /* EMC_REFRESH */
					0x00000000 /* EMC_BURST_REFRESH_NUM */
					0x000005a6 /* EMC_PRE_REFRESH_REQ_CNT */
					0x00000003 /* EMC_PDEX2WR */
					0x00000010 /* EMC_PDEX2RD */
					0x00000001 /* EMC_PCHG2PDEN */
					0x00000000 /* EMC_ACT2PDEN */
					0x0000000e /* EMC_AR2PDEN */
					0x00000018 /* EMC_RW2PDEN */
					0x000000e9 /* EMC_TXSR */
					0x00000200 /* EMC_TXSRDLL */
					0x00000005 /* EMC_TCKE */
					0x00000017 /* EMC_TFAW */
					0x00000000 /* EMC_TRPAB */
					0x00000007 /* EMC_TCLKSTABLE */
					0x00000008 /* EMC_TCLKSTOP */
					0x000016da /* EMC_TREFBW */
					0x0000000c /* EMC_QUSE_EXTRA */
					0x00000004 /* EMC_FBIO_CFG6 */
					0x00000000 /* EMC_ODT_WRITE */
					0x00000000 /* EMC_ODT_READ */
					0x00005088 /* EMC_FBIO_CFG5 */
					0xf0080191 /* EMC_CFG_DIG_DLL */
					0x00008000 /* EMC_CFG_DIG_DLL_PERIOD */
					0x0000000a /* EMC_DLL_XFORM_DQS0 */
					0x0000000a /* EMC_DLL_XFORM_DQS1 */
					0x0000000a /* EMC_DLL_XFORM_DQS2 */
					0x0000000a /* EMC_DLL_XFORM_DQS3 */
					0x0000000a /* EMC_DLL_XFORM_DQS4 */
					0x0000000a /* EMC_DLL_XFORM_DQS5 */
					0x0000000a /* EMC_DLL_XFORM_DQS6 */
					0x0000000a /* EMC_DLL_XFORM_DQS7 */
					0x00000000 /* EMC_DLL_XFORM_QUSE0 */
					0x00000000 /* EMC_DLL_XFORM_QUSE1 */
					0x00000000 /* EMC_DLL_XFORM_QUSE2 */
					0x00000000 /* EMC_DLL_XFORM_QUSE3 */
					0x00000008 /* EMC_DLL_XFORM_QUSE4 */
					0x00000008 /* EMC_DLL_XFORM_QUSE5 */
					0x00000008 /* EMC_DLL_XFORM_QUSE6 */
					0x00000008 /* EMC_DLL_XFORM_QUSE7 */
					0x00000000 /* EMC_DLI_TRIM_TXDQS0 */
					0x00000000 /* EMC_DLI_TRIM_TXDQS1 */
					0x00000000 /* EMC_DLI_TRIM_TXDQS2 */
					0x00000000 /* EMC_DLI_TRIM_TXDQS3 */
					0x00000000 /* EMC_DLI_TRIM_TXDQS4 */
					0x00000000 /* EMC_DLI_TRIM_TXDQS5 */
					0x00000000 /* EMC_DLI_TRIM_TXDQS6 */
					0x00000000 /* EMC_DLI_TRIM_TXDQS7 */
					0x0000000c /* EMC_DLL_XFORM_DQ0 */
					0x0000000c /* EMC_DLL_XFORM_DQ1 */
					0x0000000c /* EMC_DLL_XFORM_DQ2 */
					0x0000000c /* EMC_DLL_XFORM_DQ3 */
					0x000002a0 /* EMC_XM2CMDPADCTRL */
					0x0a00013d /* EMC_XM2DQSPADCTRL2 */
					0x22220000 /* EMC_XM2DQPADCTRL2 */
					0x77fff884 /* EMC_XM2CLKPADCTRL */
					0x01f1f501 /* EMC_XM2COMPPADCTRL */
					0x07077404 /* EMC_XM2VTTGENPADCTRL */
					0x54000000 /* EMC_XM2VTTGENPADCTRL2 */
					0x080001e8 /* EMC_XM2QUSEPADCTRL */
					0x0a000021 /* EMC_XM2DQSPADCTRL3 */
					0x00000802 /* EMC_CTT_TERM_CTRL */
					0x00020000 /* EMC_ZCAL_INTERVAL */
					0x00000100 /* EMC_ZCAL_WAIT_CNT */
					0x00df000c /* EMC_MRS_WAIT_CNT */
					0xa0f10404 /* EMC_AUTO_CAL_CONFIG */
					0x00000000 /* EMC_CTT */
					0x00000000 /* EMC_CTT_DURATION */
					0x80002d93 /* EMC_DYN_SELF_REF_CONTROL */
					0xf8000000 /* EMC_FBIO_SPARE */
					0xff00ff49 /* EMC_CFG_RSV */
				>;
			};
		};
	};

	hda@70030000 {
		status = "okay";
	};

	ahub@70080000 {
		i2s@70080400 {
			status = "okay";
		};
	};

	sound {
		compatible = "nvidia,tegra-audio-wm8962";
		nvidia,model = "microsoft-surface-rt-wm8962";

		nvidia,audio-routing =
			"Headphone Jack", "HPOUTR",
			"Headphone Jack", "HPOUTL",
			"Int Spk", "SPKOUTR",
			"Int Spk", "SPKOUTL";

		nvidia,i2s-controller = <&tegra_i2s1>;
		nvidia,audio-codec = <&wm8962>;

		nvidia,hp-det-gpios = <&gpio TEGRA_GPIO(W, 2) GPIO_ACTIVE_LOW>;

		clocks = <&tegra_car TEGRA30_CLK_PLL_A>,
			 <&tegra_car TEGRA30_CLK_PLL_A_OUT0>,
			 <&tegra_pmc TEGRA_PMC_CLK_OUT_1>;
		clock-names = "pll_a", "pll_a_out0", "mclk";

		assigned-clocks = <&tegra_car TEGRA30_CLK_EXTERN1>,
				  <&tegra_pmc TEGRA_PMC_CLK_OUT_1>;

		assigned-clock-parents = <&tegra_car TEGRA30_CLK_PLL_A_OUT0>,
					 <&tegra_car TEGRA30_CLK_EXTERN1>;
	};

	/* SD CARD - SDMMC-1 */
	mmc@78000000 {
		status = "okay";
		vqmmc-supply = <&ldo5_reg>;
		bus-width = <4>;
		power-gpios = <&gpio TEGRA_GPIO(D, 7) GPIO_ACTIVE_HIGH>;
		cd-gpios = <&gpio TEGRA_GPIO(I, 5) GPIO_ACTIVE_LOW>;
		wp-gpios = <&gpio TEGRA_GPIO(T, 3) GPIO_ACTIVE_HIGH>;
	};

	/* Wifi - SDMMC-3 */
	mmc@78000400 {
		#address-cells = <1>;
		#size-cells = <0>;

		status = "okay";

		bus-width = <4>;
		cap-power-off-card;
		keep-power-in-suspend;
		max-frequency = <100000000>;

		assigned-clocks = <&tegra_car TEGRA30_CLK_SDMMC3>;
		assigned-clock-parents = <&tegra_car TEGRA30_CLK_PLL_C>;
		assigned-clock-rates = <100000000>;

		mmc-pwrseq = <&mrvl_wifi_pwrseq>;
		vqmmc-supply = <&vqmmc_wifi_reg>;

		/* Marvell 88W8797 WiFi */
		wifi@1 {
			compatible = "marvell,sd8897";
			reg = <1>;
			interrupt-parent = <&gpio>;
			interrupts = <TEGRA_GPIO(U, 5) IRQ_TYPE_LEVEL_HIGH>;
		};
	};

	mrvl_wifi_pwrseq: wifi-pwrseq {
		compatible = "mmc-pwrseq-simple";

		clocks = <&tegra_pmc TEGRA_PMC_CLK_BLINK>;
		clock-names = "ext_clock";

		post-power-on-delay-ms = <300>;
		power-off-delay-us = <300>;
	};

	/* internal 32/64GB eMMC - SDMMC-4 */
	mmc@78000600 {
		status = "okay";
		bus-width = <8>;
		non-removable;
	};

	spi@7000da00 {
		status = "okay";
		spi-max-frequency = <25000000>;

		/* Boot flash - OTP read only */
		flash@1 {
			compatible = "winbond,w25q32", "jedec,spi-nor";
			reg = <1>;
			spi-max-frequency = <20000000>;
		};
	};

	usb@7d000000 {
		status = "okay";
	};

	usb-phy@7d000000 {
		status = "okay";
		vbus-supply = <&usb1_vbus_reg>;
	};

	host1x@50000000 {
		hdmi@54280000 {
			status = "okay";
			nvidia,ddc-i2c-bus = <&hdmi_ddc>;
			nvidia,hpd-gpio = <&gpio TEGRA_GPIO(N, 7) GPIO_ACTIVE_HIGH>;
		};

		dc@54200000 {
			rgb {
				status = "okay";

				port@0 {
					lcd_output: endpoint {
						remote-endpoint = <&lvds_encoder_input>;
						bus-width = <24>;
					};
				};
			};
		};
	};

	lvds-encoder {
		compatible = "idt,v103", "lvds-encoder";

		powerdown-gpios = <&gpio TEGRA_GPIO(B, 2) GPIO_ACTIVE_LOW>;

		ports {
			#address-cells = <1>;
			#size-cells = <0>;

			port@0 {
				reg = <0>;

				lvds_encoder_input: endpoint {
					remote-endpoint = <&lcd_output>;
				};
			};

			port@1 {
				reg = <1>;

				lvds_encoder_output: endpoint {
					remote-endpoint = <&panel_input>;
				};
			};
		};
	};

	panel: display-panel {
		compatible = "panel-lvds";

		power-supply = <&vdd_pnl1_reg>;
		backlight = <&backlight>;

		width-mm = <235>;
		height-mm = <132>;
		rotation = <0>;

		data-mapping = "jeida-24";

		panel-timing {
			clock-frequency = <71980000>;

			hactive = <1366>;
			vactive = <768>;

			hfront-porch = <56>;
			hsync-len = <14>;
			hback-porch = <106>;

			vfront-porch = <3>;
			vsync-len = <1>;
			vback-porch = <6>;
		};

		port {
			panel_input: endpoint {
				remote-endpoint = <&lvds_encoder_output>;
			};
		};
	};

	backlight: backlight {
		compatible = "pwm-backlight";

		enable-gpios = <&gpio TEGRA_GPIO(DD, 0) GPIO_ACTIVE_HIGH>;
		power-supply = <&vdd_5v0_sys>;
		pwms = <&pwm 0 50000>;

		brightness-levels = <1 255>;
		num-interpolated-steps = <254>;
		default-brightness-level = <128>;
	};

	pwm@7000a000 {
		status = "okay";
	};

	gpio-keys {
		compatible = "gpio-keys";

		label = "GPIO Buttons";

		power {
			label = "Power Button";
			gpios = <&gpio TEGRA_GPIO(V, 0) GPIO_ACTIVE_HIGH>;
			linux,code = <KEY_POWER>;
			debounce-interval = <10>;
			wakeup-source;
		};

		windows-button {
			label = "Windows Button";
			gpios = <&gpio TEGRA_GPIO(S, 5) GPIO_ACTIVE_HIGH>;
			linux,code = <KEY_LEFTMETA>;
			debounce-interval = <10>;
			wakeup-source;
		};

		volume-down {
			label = "Volume Down";
			gpios = <&gpio TEGRA_GPIO(S, 6) GPIO_ACTIVE_LOW>;
			linux,code = <KEY_VOLUMEDOWN>;
			debounce-interval = <10>;
		};

		volume-up {
			label = "Volume Up";
			gpios = <&gpio TEGRA_GPIO(S, 7) GPIO_ACTIVE_LOW>;
			linux,code = <KEY_VOLUMEUP>;
			debounce-interval = <10>;
		};
	};

	gpio-hall-sensor {
		compatible = "gpio-keys";

		label = "GPIO Hall Effect Sensor";

		hall-sensor {
			label = "Hall Effect Sensor";
			gpios = <&gpio TEGRA_GPIO(L, 1) GPIO_ACTIVE_HIGH>;
			linux,input-type = <EV_SW>;
			linux,code = <SW_LID>;
			linux,can-disable;
			wakeup-source;
		};
	};

	cpus {
		cpu@0 {
			cpu-supply = <&vdd_cpu>;
			operating-points-v2 = <&cpu0_opp_table>;
		};

		cpu@1 {
			cpu-supply = <&vdd_cpu>;
			operating-points-v2 = <&cpu0_opp_table>;
		};

		cpu@2 {
			cpu-supply = <&vdd_cpu>;
			operating-points-v2 = <&cpu0_opp_table>;
		};

		cpu@3 {
			cpu-supply = <&vdd_cpu>;
			operating-points-v2 = <&cpu0_opp_table>;
		};
	};

	thermal-zones {
		/*
		 * NCT1008 has two sensors:
		 *
		 *	0: internal that monitors ambient/skin temperature
		 *	1: external that is connected to the CPU's diode
		 *
		 * Ideally we should use userspace thermal governor,
		 * but it's a much more complex solution.  The "skin"
		 * zone is a simpler solution which prevents Surface RT
		 * from getting too hot from a user's tactile perspective.
		 * The CPU zone is intended to protect silicon from damage.
		 */

		skin-thermal {
			polling-delay-passive = <1000>; /* milliseconds */
			polling-delay = <5000>; /* milliseconds */

			thermal-sensors = <&nct1008 0>;

			trips {
				trip0: skin-alert {
					/* throttle at 57C until temperature drops to 56.8C */
					temperature = <57000>;
					hysteresis = <200>;
					type = "passive";
				};

				trip1: skin-crit {
					/* shut down at 65C */
					temperature = <65000>;
					hysteresis = <2000>;
					type = "critical";
				};
			};

			cooling-maps {
				map0 {
					trip = <&trip0>;
					cooling-device = <&cpu0 THERMAL_NO_LIMIT THERMAL_NO_LIMIT>,
							 <&cpu1 THERMAL_NO_LIMIT THERMAL_NO_LIMIT>,
							 <&cpu2 THERMAL_NO_LIMIT THERMAL_NO_LIMIT>,
							 <&cpu3 THERMAL_NO_LIMIT THERMAL_NO_LIMIT>,
							 <&actmon THERMAL_NO_LIMIT
								  THERMAL_NO_LIMIT>;
				};
			};
		};

		cpu-thermal {
			polling-delay-passive = <1000>; /* milliseconds */
			polling-delay = <5000>; /* milliseconds */

			thermal-sensors = <&nct1008 1>;

			trips {
				trip2: cpu-alert {
					/* throttle at 85C until temperature drops to 84.8C */
					temperature = <85000>;
					hysteresis = <200>;
					type = "passive";
				};

				trip3: cpu-crit {
					/* shut down at 90C */
					temperature = <90000>;
					hysteresis = <2000>;
					type = "critical";
				};
			};

			cooling-maps {
				map1 {
					trip = <&trip2>;
					cooling-device = <&cpu0 THERMAL_NO_LIMIT THERMAL_NO_LIMIT>,
							 <&cpu1 THERMAL_NO_LIMIT THERMAL_NO_LIMIT>,
							 <&cpu2 THERMAL_NO_LIMIT THERMAL_NO_LIMIT>,
							 <&cpu3 THERMAL_NO_LIMIT THERMAL_NO_LIMIT>,
							 <&actmon THERMAL_NO_LIMIT
								  THERMAL_NO_LIMIT>;
				};
			};
		};
	};

	vdd_5v0_sys: regulator-5v0 {
		compatible = "regulator-fixed";
		regulator-name = "vdd_5v0";
		regulator-min-microvolt = <5000000>;
		regulator-max-microvolt = <5000000>;
		regulator-always-on;
	};

	vdd_1v8_sys: regulator-1v8 {
		compatible = "regulator-fixed";
		regulator-name = "vdd_1v8_vs";
		regulator-min-microvolt = <1800000>;
		regulator-max-microvolt = <1800000>;
		regulator-always-on;
		vin-supply = <&vdd_5v0_sys>;
	};

	usb1_vbus_reg: regulator-usb1 {
		compatible = "regulator-fixed";
		regulator-name = "usb1_vbus";
		regulator-min-microvolt = <5000000>;
		regulator-max-microvolt = <5000000>;
		enable-active-high;
		gpio = <&gpio TEGRA_GPIO(DD, 6) GPIO_ACTIVE_HIGH>;
		gpio-open-drain;
		vin-supply = <&vdd_5v0_sys>;
	};

	vqmmc_wifi_reg: vddio-wifi {
		compatible = "regulator-fixed";
		regulator-name = "vqmmc_wifi";
		regulator-min-microvolt = <3300000>;
		regulator-max-microvolt = <3300000>;
		regulator-boot-on;
		regulator-always-on;
		vin-supply = <&vdd_5v0_sys>;
	};

	vdd_pnl1_reg: regulator-panel {
		compatible = "regulator-fixed";
		regulator-name = "vdd_pnl1";
		regulator-min-microvolt = <3300000>;
		regulator-max-microvolt = <3300000>;
		regulator-boot-on;
		regulator-always-on;
		gpio = <&gpio TEGRA_GPIO(DD, 2) GPIO_ACTIVE_HIGH>;
		enable-active-high;
		vin-supply = <&vdd_5v0_sys>;
	};

	vdd_cam1_ldo_reg: regulator-cam1 {
		compatible = "regulator-fixed";
		regulator-name = "vdd_cam1_ldo";
		regulator-min-microvolt = <2800000>;
		regulator-max-microvolt = <2800000>;
		enable-active-high;
		gpio = <&gpio TEGRA_GPIO(R, 6) GPIO_ACTIVE_HIGH>;
		vin-supply = <&vdd_5v0_sys>;
	};

	vdd_cam2_ldo_reg: regulator-cam2 {
		compatible = "regulator-fixed";
		regulator-name = "vdd_cam2_ldo";
		regulator-min-microvolt = <2800000>;
		regulator-max-microvolt = <2800000>;
		enable-active-high;
		gpio = <&gpio TEGRA_GPIO(R, 7) GPIO_ACTIVE_HIGH>;
		vin-supply = <&vdd_5v0_sys>;
	};

	regulator-sensors {
		compatible = "regulator-fixed";
		regulator-name = "vdd_sensor_hub";
		regulator-min-microvolt = <2800000>;
		regulator-max-microvolt = <2800000>;
		enable-active-high;
		regulator-boot-on;
		regulator-always-on;
		gpio = <&gpio TEGRA_GPIO(N, 0) GPIO_ACTIVE_HIGH>;
		vin-supply = <&vdd_5v0_sys>;
	};
};

&emc_icc_dvfs_opp_table {
	/delete-node/ opp-800000000-1300;
	/delete-node/ opp-900000000-1350;
};

&emc_bw_dfs_opp_table {
	/delete-node/ opp-800000000;
	/delete-node/ opp-900000000;
};
